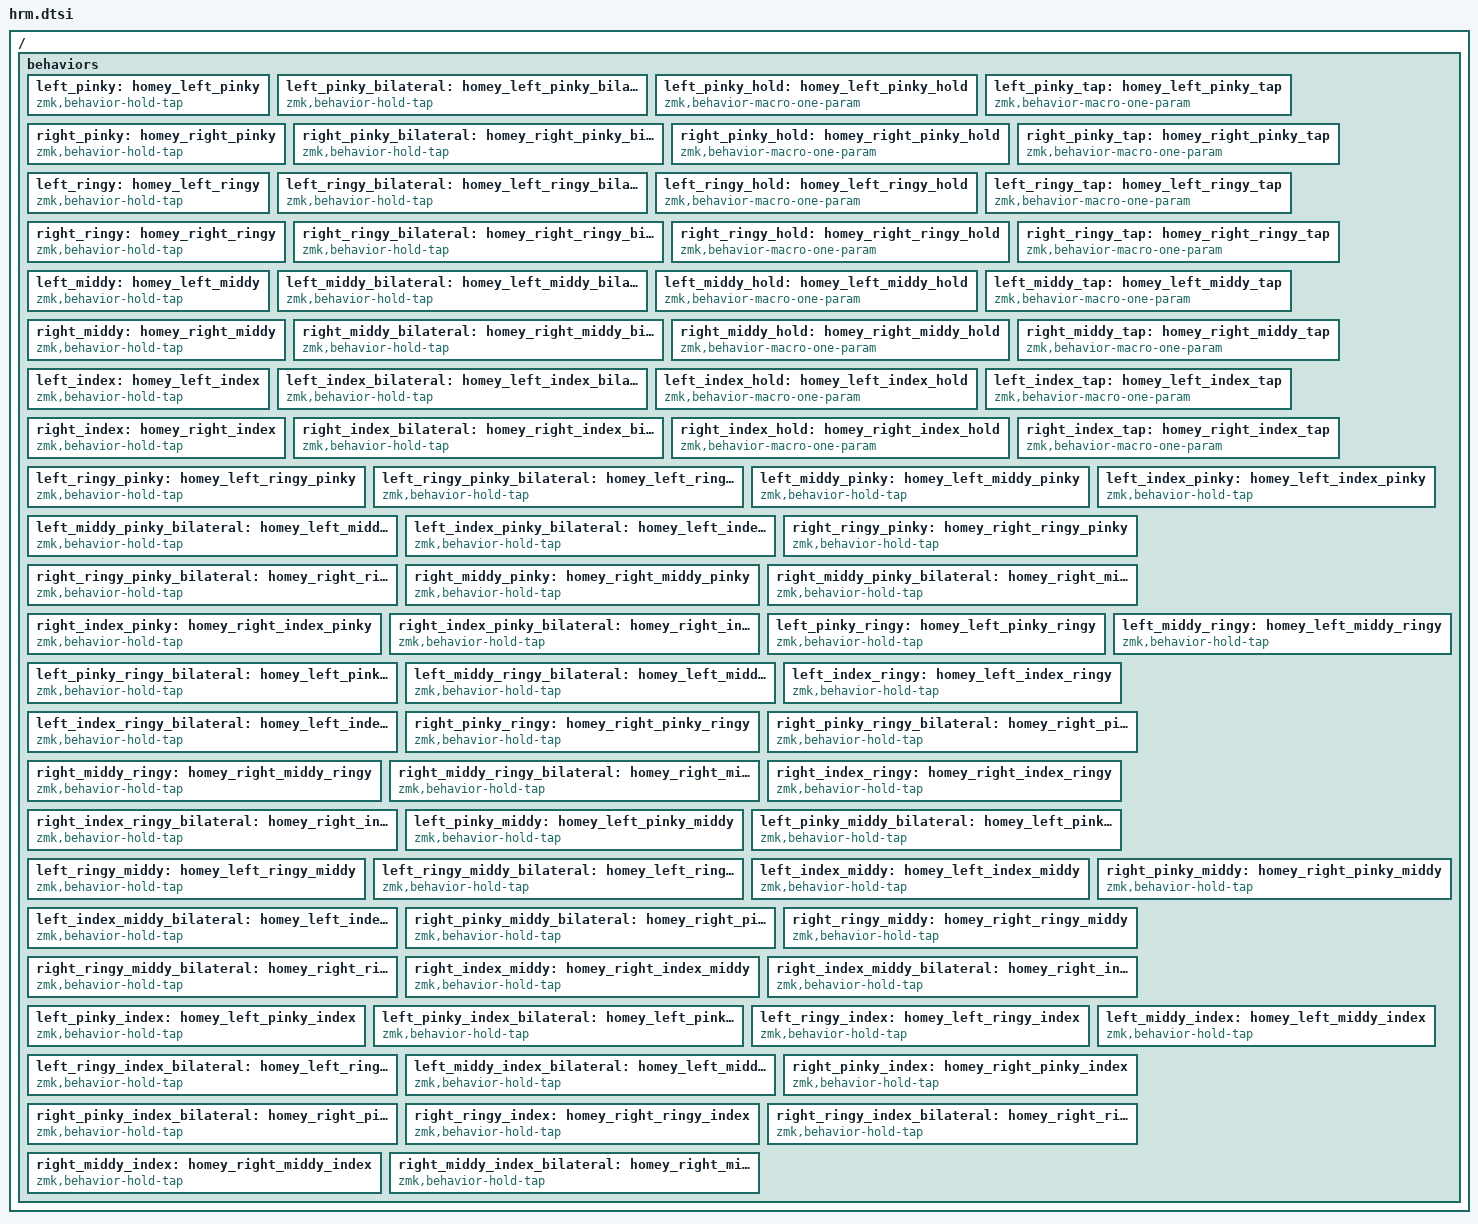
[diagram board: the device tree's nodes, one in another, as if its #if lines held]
/ {
  behaviors {

    //////////////////////////////////////////////////////////////////////////
    //
    // Miryoku layers and home row mods (ported from my QMK endgame)
    // - https://sunaku.github.io/home-row-mods.html#porting-to-zmk
    // - https://github.com/urob/zmk-config#timeless-homerow-mods
    //
    //////////////////////////////////////////////////////////////////////////

    //
    // DIFFICULTY_LEVEL specifies your level of expertise with this keymap.
    // It's meant to help newcomers gradually work their way up to mastery.
    //
    // #define DIFFICULTY_LEVEL 1 // novice (500ms)
    // #define DIFFICULTY_LEVEL 2 // slower (400ms)
    // #define DIFFICULTY_LEVEL 3 // normal (300ms)
    // #define DIFFICULTY_LEVEL 4 // faster (200ms)
    // #define DIFFICULTY_LEVEL 5 // expert (100ms)
    //
    // You can disable this setting by omitting it or assigning a `0` zero,
    // in which case it will default to my personal set of time thresholds.
    //
    // #define DIFFICULTY_LEVEL 0 // sunaku (150ms)
    //
    // No matter what difficulty level you choose, you can always override
    // any settings in this keymap at the beginning of this configuration.
    //
    #ifdef DIFFICULTY_LEVEL
      #if DIFFICULTY_LEVEL > 0 && DIFFICULTY_LEVEL < 6
        #ifndef TAPPING_RESOLUTION
          #define TAPPING_RESOLUTION ((6 - DIFFICULTY_LEVEL) * 100)
        #endif
      #endif
    #endif

    //
    // TAPPING_RESOLUTION specifies the maximum speed at which the keyboard
    // confuses your taps as being holds when you type on home row mod keys.
    // When you lower this value, the same confusion should still occur; but
    // when you raise this value, you should be able to type normally again.
    //
    #ifndef TAPPING_RESOLUTION
    #define TAPPING_RESOLUTION 150
    #endif

    //
    // ENFORCE_BILATERAL cancels out single-handed home row mods activation by
    // releasing any currently pressed mods and replacing them with plain taps.
    //
    // NOTE: You may still encounter "flashing mods" where an operating system
    // action is triggered by the release of mods, such as LGUI which launches
    // the Windows Start Menu and LALT which opens the Microsoft Office Ribbon.
    //
    //#define ENFORCE_BILATERAL

    //
    // SHIFT_FORGIVENESS taps when home row shift is merely held and released,
    // without any other key having been tapped while the shift was held down.
    // For example, suppose you hold a home row shift key and, before pressing
    // another key, you suddenly decide that you don't want the shift anymore:
    //
    // <1> If this setting is enabled, the underlying tap behavior is triggered
    //     to type a single character when you release that home row shift key.
    //
    // <2> Otherwise, nothing happens when you release that home row shift key.
    //
    // This requires the "hold-while-undecided" ZMK feature in a beta firmware:
    // please select "v24.08-beta1" or newer from the drop-down menu located at
    // Glove80 Layout Editor > Settings > Advanced Settings > Firmware Version.
    //
    // CAUTION: This can interfere with mod-click mouse usage where you hold a
    // home row shift key and perform mouse actions (move, click, drag & drop):
    // when you release that home row shift key, its underlying character would
    // be typed, potentially triggering an unexpected action on your selection!
    // To prevent the underlying character from being typed, press another key
    // (such as a dedicated shift key, a neighboring home row mod key, or even
    // a layer access key) before you release the original home row shift key.
    //
    // NOTE: You may potentially encounter "flashing mods" where an application
    // or operating system action is triggered by a standalone tap of a shift,
    // but this is unlikely as people regularly tap shift without consequence.
    //
    //#define SHIFT_FORGIVENESS

    //
    // THUMB_FORGIVENESS taps when a thumb layer access key is merely held and
    // released, without any other key having been tapped while thumb was held.
    // For example, suppose you hold the cursor layer key and, before pressing
    // another key, you suddenly decide that you don't want the layer anymore:
    //
    // <1> If this setting is enabled, the underlying tap behavior is triggered
    //     to type a single character when you release that layer access key.
    //
    // <2> Otherwise, nothing happens when you release that layer access key.
    //
    // NOTE: This setting interferes with (and effectively disables) per-key
    // RGB indicators (PR30) for layers accessed via thumb layer access keys.
    //
    //#define THUMB_FORGIVENESS

    //
    // SPACE_FORGIVENESS taps when the symbol layer access key is merely held
    // and released, without any symbol been tapped while the access was held.
    // For example, suppose you hold the symbol layer key and, before pressing
    // another key, you suddenly decide that you don't want the layer anymore:
    //
    // <1> If this setting is enabled, the underlying tap behavior is triggered
    //     to type a single character when you release that layer access key.
    //
    // <2> Otherwise, nothing happens when you release that layer access key.
    //
    // NOTE: This setting interferes with (and effectively disables) per-key
    // RGB indicators (PR30) for layers accessed via thumb layer access keys.
    //
    //#define SPACE_FORGIVENESS

    //
    // The *_FINGER_MOD specify which modifiers are used by home row mod keys.
    // Here, we use Miryoku's "GACS" (Win, Alt, Ctrl, Shift) order by default,
    // unless OPERATING_SYSTEM is macOS, in which case Win & Ctrl are swapped,
    // unless MACOS_USE_GACS is also defined to suppress that Win & Ctrl swap.
    //
    #ifndef PINKY_FINGER_MOD
      #if OPERATING_SYSTEM == 'M' && !defined(MACOS_USE_GACS)
        #define PINKY_FINGER_MOD LCTL
      #else
        #define PINKY_FINGER_MOD LGUI
      #endif
    #endif
    #ifndef RINGY_FINGER_MOD
    #define RINGY_FINGER_MOD LALT
    #endif
    #ifndef MIDDY_FINGER_MOD
      #if OPERATING_SYSTEM == 'M' && !defined(MACOS_USE_GACS)
        #define MIDDY_FINGER_MOD LGUI
      #else
        #define MIDDY_FINGER_MOD LCTL
      #endif
    #endif
    #ifndef INDEX_FINGER_MOD
    #define INDEX_FINGER_MOD LSFT
    #endif
    //
    // The following settings let you configure mods individually, per finger:
    //
    #ifndef LEFT_PINKY_MOD
    #define LEFT_PINKY_MOD PINKY_FINGER_MOD
    #endif
    #ifndef RIGHT_PINKY_MOD
    #define RIGHT_PINKY_MOD PINKY_FINGER_MOD
    #endif
    #ifndef LEFT_RINGY_MOD
    #define LEFT_RINGY_MOD RINGY_FINGER_MOD
    #endif
    #ifndef RIGHT_RINGY_MOD
    #define RIGHT_RINGY_MOD RINGY_FINGER_MOD
    #endif
    #ifndef LEFT_MIDDY_MOD
    #define LEFT_MIDDY_MOD MIDDY_FINGER_MOD
    #endif
    #ifndef RIGHT_MIDDY_MOD
    #define RIGHT_MIDDY_MOD MIDDY_FINGER_MOD
    #endif
    #ifndef LEFT_INDEX_MOD
    #define LEFT_INDEX_MOD INDEX_FINGER_MOD
    #endif
    #ifndef RIGHT_INDEX_MOD
    #define RIGHT_INDEX_MOD INDEX_FINGER_MOD
    #endif

    //
    // HOMEY_HOLDING_TYPE defines the flavor of ZMK hold-tap behavior to use
    // for the pinky, ring, and middle fingers (which are assigned to Super,
    // Alt, and Ctrl respectively in the Miryoku system) on home row keys.
    //
    #ifndef HOMEY_HOLDING_TYPE
    #define HOMEY_HOLDING_TYPE "tap-preferred"
    #endif

    //
    // HOMEY_HOLDING_TIME defines how long you need to hold (milliseconds)
    // home row mod keys in order to send their modifiers to the computer
    // (i.e. "register" them) for mod-click mouse usage (e.g. Ctrl-Click).
    //
    #ifndef HOMEY_HOLDING_TIME
    #define HOMEY_HOLDING_TIME (TAPPING_RESOLUTION + 90)
    #endif
    #ifndef INDEX_HOLDING_TIME
    #define INDEX_HOLDING_TIME (TAPPING_RESOLUTION + 20)
    #endif
    #ifndef MIDDY_HOLDING_TIME
    #define MIDDY_HOLDING_TIME (TAPPING_RESOLUTION + 60)
    #endif
    #ifndef RINGY_HOLDING_TIME
    #define RINGY_HOLDING_TIME (TAPPING_RESOLUTION + 90)
    #endif
    #ifndef PINKY_HOLDING_TIME
    #define PINKY_HOLDING_TIME (TAPPING_RESOLUTION + 110)
    #endif

    //
    // HOMEY_STREAK_DECAY defines how long you need to wait (milliseconds)
    // after typing before you can use home row mods again.  It prevents
    // unintended activation of home row mods when you're actively typing.
    //
    #ifndef HOMEY_STREAK_DECAY
    #define HOMEY_STREAK_DECAY TAPPING_RESOLUTION
    #endif

    //
    // HOMEY_REPEAT_DECAY defines how much time you have left (milliseconds)
    // after tapping a key to hold it again in order to make it auto-repeat.
    //
    #ifndef HOMEY_REPEAT_DECAY
    #define HOMEY_REPEAT_DECAY (TAPPING_RESOLUTION + 150)
    #endif // "tap then hold" for key auto-repeat

    //
    // CHORD_HOLDING_TYPE defines the flavor of ZMK hold-tap behavior to use
    // for chorded home row mods (secondary keypresses in multi-mod chords).
    //
    #ifndef CHORD_HOLDING_TYPE
    #define CHORD_HOLDING_TYPE HOMEY_HOLDING_TYPE
    #endif

    //
    // CHORD_HOLDING_TIME defines how long you need to hold (milliseconds)
    // home row mod keys in order to send their modifiers to the computer
    // (i.e. "register" them) for mod-click mouse usage (e.g. Ctrl-Click).
    // This is specifically for secondary keypresses in multi-mod chords.
    //
    #ifndef CHORD_HOLDING_TIME
    #define CHORD_HOLDING_TIME TAPPING_RESOLUTION
    #endif

    //
    // CHORD_STREAK_DECAY defines how long you need to wait (milliseconds)
    // after typing before you can use home row mods again.  It prevents
    // unintended activation of home row mods when you're actively typing
    // This is specifically for secondary keypresses in multi-mod chords.
    //
    #ifndef CHORD_STREAK_DECAY
    #define CHORD_STREAK_DECAY HOMEY_STREAK_DECAY
    #endif

    //
    // CHORD_REPEAT_DECAY defines how much time you have left (milliseconds)
    // after tapping a key to hold it again in order to make it auto-repeat.
    // This is specifically for secondary keypresses in multi-mod chords.
    //
    #ifndef CHORD_REPEAT_DECAY
    #define CHORD_REPEAT_DECAY HOMEY_REPEAT_DECAY
    #endif

    //
    // INDEX_HOLDING_TYPE defines the flavor of ZMK hold-tap behavior to use
    // for index fingers (which Miryoku assigns to Shift) on home row keys.
    //
    // NOTE: The "tap-preferred" flavor of ZMK hold-tap for index finger keys
    // allows faster activation of the Shift modifier (without having to wait
    // for the modified key to be released as the "balanced" flavor requires).
    //
    #ifndef INDEX_HOLDING_TYPE
    #define INDEX_HOLDING_TYPE "tap-preferred"
    #endif

    //
    // INDEX_STREAK_DECAY defines how long you need to wait (milliseconds)
    // after typing before you can use home row mods again.  It prevents
    // unintended activation of home row mods when you're actively typing.
    //
    #ifndef INDEX_STREAK_DECAY
    #define INDEX_STREAK_DECAY (TAPPING_RESOLUTION - 50)
    #endif

    //
    // INDEX_REPEAT_DECAY defines how much time you have left (milliseconds)
    // after tapping a key to hold it again in order to make it auto-repeat.
    //
    #ifndef INDEX_REPEAT_DECAY
    #define INDEX_REPEAT_DECAY (TAPPING_RESOLUTION + 150)
    #endif // "tap then hold" for key auto-repeat

    //
    // PLAIN_HOLDING_TYPE defines the flavor of ZMK hold-tap behavior to use
    // for index fingers (which Miryoku assigns to Shift) on home row keys.
    //
    // NOTE: The "tap-preferred" flavor of ZMK hold-tap for index finger keys
    // allows faster activation of the Shift modifier (without having to wait
    // for the modified key to be released as the "balanced" flavor requires).
    //
    #ifndef PLAIN_HOLDING_TYPE
    #define PLAIN_HOLDING_TYPE INDEX_HOLDING_TYPE
    #endif

    //
    // PLAIN_HOLDING_TIME defines how long you need to hold (milliseconds)
    // index finger keys in order to send their modifiers to the computer
    // (i.e. "register" them) for mod-click mouse usage (e.g. Shift-Click).
    //
    #ifndef PLAIN_HOLDING_TIME
    #define PLAIN_HOLDING_TIME (TAPPING_RESOLUTION + 50)
    #endif

    //
    // PLAIN_STREAK_DECAY defines how long you need to wait (milliseconds)
    // after typing before you can use home row mods again.  It prevents
    // unintended activation of home row mods when you're actively typing.
    //
    #ifndef PLAIN_STREAK_DECAY
    #define PLAIN_STREAK_DECAY HOMEY_STREAK_DECAY
    #endif

    //
    // PLAIN_REPEAT_DECAY defines how much time you have left (milliseconds)
    // after tapping a key to hold it again in order to make it auto-repeat.
    //
    #ifndef PLAIN_REPEAT_DECAY
    #define PLAIN_REPEAT_DECAY (TAPPING_RESOLUTION + 150)
    #endif // "tap then hold" for key auto-repeat

    //
    // THUMB_HOLDING_TYPE defines the flavor of ZMK hold-tap behavior to use
    // for the thumbs (which are assigned to 6 layers in the Miryoku system).
    //
    // NOTE: The "balanced" flavor of ZMK hold-tap provides instant modifier
    // activation for the symbol layer (if the tapped symbol key is released
    // while the thumb layer key is still held down) for quicker programming.
    //
    #ifndef THUMB_HOLDING_TYPE
    #define THUMB_HOLDING_TYPE "balanced"
    #endif

    //
    // THUMB_HOLDING_TIME defines how long you need to hold (milliseconds)
    // a thumb key to activate a layer.  Shorter holds are treated as taps.
    //
    #ifndef THUMB_HOLDING_TIME
    #define THUMB_HOLDING_TIME (TAPPING_RESOLUTION + 50)
    #endif

    //
    // THUMB_REPEAT_DECAY defines how much time you have left (milliseconds)
    // after tapping a key to hold it again in order to make it auto-repeat.
    //
    #ifndef THUMB_REPEAT_DECAY
    #define THUMB_REPEAT_DECAY (TAPPING_RESOLUTION + 150)
    #endif // "tap then hold" for key auto-repeat

    //
    // SPACE_HOLDING_TYPE defines the flavor of ZMK hold-tap behavior to use
    // for spacebar (assigned to the right thumb's home position by default).
    //
    #ifndef SPACE_HOLDING_TYPE
    #define SPACE_HOLDING_TYPE THUMB_HOLDING_TYPE
    #endif

    //
    // SPACE_HOLDING_TIME defines how long you need to hold (milliseconds)
    // the space thumb key to activate.  Shorter holds are treated as taps.
    //
    #ifndef SPACE_HOLDING_TIME
    #define SPACE_HOLDING_TIME (TAPPING_RESOLUTION + 20)
    #endif

    //
    // SPACE_REPEAT_DECAY defines how much time you have left (milliseconds)
    // after tapping a key to hold it again in order to make it auto-repeat.
    //
    #ifndef SPACE_REPEAT_DECAY
    #define SPACE_REPEAT_DECAY TAPPING_RESOLUTION
    #endif

    //        34 KEY MATRIX / LAYOUT MAPPING
    //
    // ╭────────────────────┬────────────────────╮
    // │  0   1   2   3   4 │  5   6   7   8   9 │
    // │ 10  11  12  13  14 │ 15  16  17  18  19 │
    // │ 20  21  22  23  24 │ 25  26  27  28  29 │
    // ╰───────────╮ 30  31 │ 32  33 ╭───────────╯
    //             ╰────────┴────────╯
    #define LEFT_HAND_KEYS  \
            0  1  2  3  4   \
           10 11 12 13 14   \
           20 21 22 23 24
    #define RIGHT_HAND_KEYS \
            5  6  7  8  9   \
           15 16 17 18 19   \
           25 26 27 28 29
    #define THUMB_KEYS      \
           30 31    32 33

    #define LEFT_PINKY_KEY  A
    #define LEFT_RINGY_KEY  O
    #define LEFT_MIDDY_KEY  E
    #define LEFT_INDEX_KEY  U

    #define RIGHT_INDEX_KEY H
    #define RIGHT_MIDDY_KEY T
    #define RIGHT_RINGY_KEY N
    #define RIGHT_PINKY_KEY S

    //
    // Home row mods with bilateral combinations support
    //
    #ifndef PINKY_HOLDING_TYPE
    #define PINKY_HOLDING_TYPE HOMEY_HOLDING_TYPE
    #endif
    #ifndef PINKY_CHORD_HOLDING_TYPE
    #define PINKY_CHORD_HOLDING_TYPE CHORD_HOLDING_TYPE
    #endif
    #ifndef LEFT_PINKY_CHORD_HOLDING_TYPE
    #define LEFT_PINKY_CHORD_HOLDING_TYPE PINKY_CHORD_HOLDING_TYPE
    #endif
    #ifndef RIGHT_PINKY_CHORD_HOLDING_TYPE
    #define RIGHT_PINKY_CHORD_HOLDING_TYPE PINKY_CHORD_HOLDING_TYPE
    #endif
    #ifndef PINKY_HOLDING_TIME
    #define PINKY_HOLDING_TIME HOMEY_HOLDING_TIME
    #endif
    #ifndef PINKY_CHORD_HOLDING_TIME
    #define PINKY_CHORD_HOLDING_TIME CHORD_HOLDING_TIME
    #endif
    #ifndef LEFT_PINKY_CHORD_HOLDING_TIME
    #define LEFT_PINKY_CHORD_HOLDING_TIME PINKY_CHORD_HOLDING_TIME
    #endif
    #ifndef RIGHT_PINKY_CHORD_HOLDING_TIME
    #define RIGHT_PINKY_CHORD_HOLDING_TIME PINKY_CHORD_HOLDING_TIME
    #endif
    #ifndef PINKY_STREAK_DECAY
    #define PINKY_STREAK_DECAY HOMEY_STREAK_DECAY
    #endif
    #ifndef PINKY_CHORD_STREAK_DECAY
    #define PINKY_CHORD_STREAK_DECAY CHORD_STREAK_DECAY
    #endif
    #ifndef LEFT_PINKY_CHORD_STREAK_DECAY
    #define LEFT_PINKY_CHORD_STREAK_DECAY PINKY_CHORD_STREAK_DECAY
    #endif
    #ifndef RIGHT_PINKY_CHORD_STREAK_DECAY
    #define RIGHT_PINKY_CHORD_STREAK_DECAY PINKY_CHORD_STREAK_DECAY
    #endif
    #ifndef PINKY_REPEAT_DECAY
    #define PINKY_REPEAT_DECAY HOMEY_REPEAT_DECAY
    #endif
    #ifndef PINKY_CHORD_REPEAT_DECAY
    #define PINKY_CHORD_REPEAT_DECAY CHORD_REPEAT_DECAY
    #endif
    #ifndef LEFT_PINKY_CHORD_REPEAT_DECAY
    #define LEFT_PINKY_CHORD_REPEAT_DECAY PINKY_CHORD_REPEAT_DECAY
    #endif
    #ifndef RIGHT_PINKY_CHORD_REPEAT_DECAY
    #define RIGHT_PINKY_CHORD_REPEAT_DECAY PINKY_CHORD_REPEAT_DECAY
    #endif
    #ifndef RINGY_HOLDING_TYPE
    #define RINGY_HOLDING_TYPE HOMEY_HOLDING_TYPE
    #endif
    #ifndef RINGY_CHORD_HOLDING_TYPE
    #define RINGY_CHORD_HOLDING_TYPE CHORD_HOLDING_TYPE
    #endif
    #ifndef LEFT_RINGY_CHORD_HOLDING_TYPE
    #define LEFT_RINGY_CHORD_HOLDING_TYPE RINGY_CHORD_HOLDING_TYPE
    #endif
    #ifndef RIGHT_RINGY_CHORD_HOLDING_TYPE
    #define RIGHT_RINGY_CHORD_HOLDING_TYPE RINGY_CHORD_HOLDING_TYPE
    #endif
    #ifndef RINGY_HOLDING_TIME
    #define RINGY_HOLDING_TIME HOMEY_HOLDING_TIME
    #endif
    #ifndef RINGY_CHORD_HOLDING_TIME
    #define RINGY_CHORD_HOLDING_TIME CHORD_HOLDING_TIME
    #endif
    #ifndef LEFT_RINGY_CHORD_HOLDING_TIME
    #define LEFT_RINGY_CHORD_HOLDING_TIME RINGY_CHORD_HOLDING_TIME
    #endif
    #ifndef RIGHT_RINGY_CHORD_HOLDING_TIME
    #define RIGHT_RINGY_CHORD_HOLDING_TIME RINGY_CHORD_HOLDING_TIME
    #endif
    #ifndef RINGY_STREAK_DECAY
    #define RINGY_STREAK_DECAY HOMEY_STREAK_DECAY
    #endif
    #ifndef RINGY_CHORD_STREAK_DECAY
    #define RINGY_CHORD_STREAK_DECAY CHORD_STREAK_DECAY
    #endif
    #ifndef LEFT_RINGY_CHORD_STREAK_DECAY
    #define LEFT_RINGY_CHORD_STREAK_DECAY RINGY_CHORD_STREAK_DECAY
    #endif
    #ifndef RIGHT_RINGY_CHORD_STREAK_DECAY
    #define RIGHT_RINGY_CHORD_STREAK_DECAY RINGY_CHORD_STREAK_DECAY
    #endif
    #ifndef RINGY_REPEAT_DECAY
    #define RINGY_REPEAT_DECAY HOMEY_REPEAT_DECAY
    #endif
    #ifndef RINGY_CHORD_REPEAT_DECAY
    #define RINGY_CHORD_REPEAT_DECAY CHORD_REPEAT_DECAY
    #endif
    #ifndef LEFT_RINGY_CHORD_REPEAT_DECAY
    #define LEFT_RINGY_CHORD_REPEAT_DECAY RINGY_CHORD_REPEAT_DECAY
    #endif
    #ifndef RIGHT_RINGY_CHORD_REPEAT_DECAY
    #define RIGHT_RINGY_CHORD_REPEAT_DECAY RINGY_CHORD_REPEAT_DECAY
    #endif
    #ifndef MIDDY_HOLDING_TYPE
    #define MIDDY_HOLDING_TYPE HOMEY_HOLDING_TYPE
    #endif
    #ifndef MIDDY_CHORD_HOLDING_TYPE
    #define MIDDY_CHORD_HOLDING_TYPE CHORD_HOLDING_TYPE
    #endif
    #ifndef LEFT_MIDDY_CHORD_HOLDING_TYPE
    #define LEFT_MIDDY_CHORD_HOLDING_TYPE MIDDY_CHORD_HOLDING_TYPE
    #endif
    #ifndef RIGHT_MIDDY_CHORD_HOLDING_TYPE
    #define RIGHT_MIDDY_CHORD_HOLDING_TYPE MIDDY_CHORD_HOLDING_TYPE
    #endif
    #ifndef MIDDY_HOLDING_TIME
    #define MIDDY_HOLDING_TIME HOMEY_HOLDING_TIME
    #endif
    #ifndef MIDDY_CHORD_HOLDING_TIME
    #define MIDDY_CHORD_HOLDING_TIME CHORD_HOLDING_TIME
    #endif
    #ifndef LEFT_MIDDY_CHORD_HOLDING_TIME
    #define LEFT_MIDDY_CHORD_HOLDING_TIME MIDDY_CHORD_HOLDING_TIME
    #endif
    #ifndef RIGHT_MIDDY_CHORD_HOLDING_TIME
    #define RIGHT_MIDDY_CHORD_HOLDING_TIME MIDDY_CHORD_HOLDING_TIME
    #endif
    #ifndef MIDDY_STREAK_DECAY
    #define MIDDY_STREAK_DECAY HOMEY_STREAK_DECAY
    #endif
    #ifndef MIDDY_CHORD_STREAK_DECAY
    #define MIDDY_CHORD_STREAK_DECAY CHORD_STREAK_DECAY
    #endif
    #ifndef LEFT_MIDDY_CHORD_STREAK_DECAY
    #define LEFT_MIDDY_CHORD_STREAK_DECAY MIDDY_CHORD_STREAK_DECAY
    #endif
    #ifndef RIGHT_MIDDY_CHORD_STREAK_DECAY
    #define RIGHT_MIDDY_CHORD_STREAK_DECAY MIDDY_CHORD_STREAK_DECAY
    #endif
    #ifndef MIDDY_REPEAT_DECAY
    #define MIDDY_REPEAT_DECAY HOMEY_REPEAT_DECAY
    #endif
    #ifndef MIDDY_CHORD_REPEAT_DECAY
    #define MIDDY_CHORD_REPEAT_DECAY CHORD_REPEAT_DECAY
    #endif
    #ifndef LEFT_MIDDY_CHORD_REPEAT_DECAY
    #define LEFT_MIDDY_CHORD_REPEAT_DECAY MIDDY_CHORD_REPEAT_DECAY
    #endif
    #ifndef RIGHT_MIDDY_CHORD_REPEAT_DECAY
    #define RIGHT_MIDDY_CHORD_REPEAT_DECAY MIDDY_CHORD_REPEAT_DECAY
    #endif
    #ifndef INDEX_HOLDING_TYPE
    #define INDEX_HOLDING_TYPE HOMEY_HOLDING_TYPE
    #endif
    #ifndef INDEX_CHORD_HOLDING_TYPE
    #define INDEX_CHORD_HOLDING_TYPE CHORD_HOLDING_TYPE
    #endif
    #ifndef LEFT_INDEX_CHORD_HOLDING_TYPE
    #define LEFT_INDEX_CHORD_HOLDING_TYPE INDEX_CHORD_HOLDING_TYPE
    #endif
    #ifndef RIGHT_INDEX_CHORD_HOLDING_TYPE
    #define RIGHT_INDEX_CHORD_HOLDING_TYPE INDEX_CHORD_HOLDING_TYPE
    #endif
    #ifndef INDEX_HOLDING_TIME
    #define INDEX_HOLDING_TIME HOMEY_HOLDING_TIME
    #endif
    #ifndef INDEX_CHORD_HOLDING_TIME
    #define INDEX_CHORD_HOLDING_TIME CHORD_HOLDING_TIME
    #endif
    #ifndef LEFT_INDEX_CHORD_HOLDING_TIME
    #define LEFT_INDEX_CHORD_HOLDING_TIME INDEX_CHORD_HOLDING_TIME
    #endif
    #ifndef RIGHT_INDEX_CHORD_HOLDING_TIME
    #define RIGHT_INDEX_CHORD_HOLDING_TIME INDEX_CHORD_HOLDING_TIME
    #endif
    #ifndef INDEX_STREAK_DECAY
    #define INDEX_STREAK_DECAY HOMEY_STREAK_DECAY
    #endif
    #ifndef INDEX_CHORD_STREAK_DECAY
    #define INDEX_CHORD_STREAK_DECAY CHORD_STREAK_DECAY
    #endif
    #ifndef LEFT_INDEX_CHORD_STREAK_DECAY
    #define LEFT_INDEX_CHORD_STREAK_DECAY INDEX_CHORD_STREAK_DECAY
    #endif
    #ifndef RIGHT_INDEX_CHORD_STREAK_DECAY
    #define RIGHT_INDEX_CHORD_STREAK_DECAY INDEX_CHORD_STREAK_DECAY
    #endif
    #ifndef INDEX_REPEAT_DECAY
    #define INDEX_REPEAT_DECAY HOMEY_REPEAT_DECAY
    #endif
    #ifndef INDEX_CHORD_REPEAT_DECAY
    #define INDEX_CHORD_REPEAT_DECAY CHORD_REPEAT_DECAY
    #endif
    #ifndef LEFT_INDEX_CHORD_REPEAT_DECAY
    #define LEFT_INDEX_CHORD_REPEAT_DECAY INDEX_CHORD_REPEAT_DECAY
    #endif
    #ifndef RIGHT_INDEX_CHORD_REPEAT_DECAY
    #define RIGHT_INDEX_CHORD_REPEAT_DECAY INDEX_CHORD_REPEAT_DECAY
    #endif
    #ifndef LEFT_PINKY_HOLDING_TYPE
    #define LEFT_PINKY_HOLDING_TYPE PINKY_HOLDING_TYPE
    #endif
    #ifndef LEFT_PINKY_HOLDING_TIME
    #define LEFT_PINKY_HOLDING_TIME PINKY_HOLDING_TIME
    #endif
    #ifndef LEFT_PINKY_STREAK_DECAY
    #define LEFT_PINKY_STREAK_DECAY PINKY_STREAK_DECAY
    #endif
    #ifndef LEFT_PINKY_REPEAT_DECAY
    #define LEFT_PINKY_REPEAT_DECAY PINKY_REPEAT_DECAY
    #endif
    left_pinky: homey_left_pinky {
      compatible = "zmk,behavior-hold-tap";
      flavor = LEFT_PINKY_HOLDING_TYPE;
      hold-trigger-key-positions = <RIGHT_HAND_KEYS THUMB_KEYS>;
      hold-trigger-on-release; // wait for other home row mods
      tapping-term-ms = <LEFT_PINKY_HOLDING_TIME>;
      quick-tap-ms = <LEFT_PINKY_REPEAT_DECAY>;
      require-prior-idle-ms = <LEFT_PINKY_STREAK_DECAY>;
      #binding-cells = <2>;
      bindings = <&kp>, <&kp>;
      #ifdef SHIFT_FORGIVENESS
      #if LEFT_PINKY_MOD == LSFT || LEFT_PINKY_MOD == RSFT
      hold-while-undecided; // requires 24.08-beta1 or newer firmware
      retro-tap; // tap on standalone hold
      #endif
      #endif
    };
    left_pinky_bilateral: homey_left_pinky_bilateral {
      compatible = "zmk,behavior-hold-tap";
      flavor = LEFT_PINKY_HOLDING_TYPE;
      hold-trigger-key-positions = <RIGHT_HAND_KEYS THUMB_KEYS>;
      hold-trigger-on-release; // wait for other home row mods
      tapping-term-ms = <LEFT_PINKY_HOLDING_TIME>;
      quick-tap-ms = <LEFT_PINKY_REPEAT_DECAY>;
      require-prior-idle-ms = <LEFT_PINKY_STREAK_DECAY>;
      #binding-cells = <2>;
      bindings = <&left_pinky_hold>, <&kp>;
      #ifdef SHIFT_FORGIVENESS
      #if LEFT_PINKY_MOD == LSFT || LEFT_PINKY_MOD == RSFT
      hold-while-undecided; // requires 24.08-beta1 or newer firmware
      retro-tap; // tap on standalone hold
      #endif
      #endif
    };
    left_pinky_hold: homey_left_pinky_hold {
      compatible = "zmk,behavior-macro-one-param";
      wait-ms = <0>;
      tap-ms = <0>;
      #binding-cells = <1>;
      bindings
        = <&macro_param_1to1>
        , <&macro_press &kp MACRO_PLACEHOLDER>
        #ifdef LAYER_LeftPinky
        , <&macro_press &mo LAYER_LeftPinky>
        #endif
        , <&macro_pause_for_release>
        , <&macro_param_1to1>
        , <&macro_release &kp MACRO_PLACEHOLDER>
        #ifdef LAYER_LeftPinky
        , <&macro_release &mo LAYER_LeftPinky>
        #endif
        ;
    };
    left_pinky_tap: homey_left_pinky_tap {
      compatible = "zmk,behavior-macro-one-param";
      wait-ms = <0>;
      tap-ms = <0>;
      #binding-cells = <1>;
      bindings
        = <&macro_release
            &kp LSFT &kp RSFT
            &kp LALT &kp RALT
            &kp LCTL &kp RCTL
            &kp LGUI &kp RGUI>
        , <&macro_tap &kp LEFT_PINKY_KEY>
        , <&macro_param_1to1>
        , <&macro_tap &kp MACRO_PLACEHOLDER>
        ;
    };
    #define LeftPinky(key) LeftPinky_layer0(key)
    #ifdef ENFORCE_BILATERAL
    #define left_pinky_layer0_variant left_pinky_bilateral
    #else
    #define left_pinky_layer0_variant left_pinky
    #endif
    #define LeftPinky_layer0(key) left_pinky_layer0_variant LEFT_PINKY_MOD key
    #ifndef RIGHT_PINKY_HOLDING_TYPE
    #define RIGHT_PINKY_HOLDING_TYPE PINKY_HOLDING_TYPE
    #endif
    #ifndef RIGHT_PINKY_HOLDING_TIME
    #define RIGHT_PINKY_HOLDING_TIME PINKY_HOLDING_TIME
    #endif
    #ifndef RIGHT_PINKY_STREAK_DECAY
    #define RIGHT_PINKY_STREAK_DECAY PINKY_STREAK_DECAY
    #endif
    #ifndef RIGHT_PINKY_REPEAT_DECAY
    #define RIGHT_PINKY_REPEAT_DECAY PINKY_REPEAT_DECAY
    #endif
    right_pinky: homey_right_pinky {
      compatible = "zmk,behavior-hold-tap";
      flavor = RIGHT_PINKY_HOLDING_TYPE;
      hold-trigger-key-positions = <LEFT_HAND_KEYS THUMB_KEYS>;
      hold-trigger-on-release; // wait for other home row mods
      tapping-term-ms = <RIGHT_PINKY_HOLDING_TIME>;
      quick-tap-ms = <RIGHT_PINKY_REPEAT_DECAY>;
      require-prior-idle-ms = <RIGHT_PINKY_STREAK_DECAY>;
      #binding-cells = <2>;
      bindings = <&kp>, <&kp>;
      #ifdef SHIFT_FORGIVENESS
      #if RIGHT_PINKY_MOD == LSFT || RIGHT_PINKY_MOD == RSFT
      hold-while-undecided; // requires 24.08-beta1 or newer firmware
      retro-tap; // tap on standalone hold
      #endif
      #endif
    };
    right_pinky_bilateral: homey_right_pinky_bilateral {
      compatible = "zmk,behavior-hold-tap";
      flavor = RIGHT_PINKY_HOLDING_TYPE;
      hold-trigger-key-positions = <LEFT_HAND_KEYS THUMB_KEYS>;
      hold-trigger-on-release; // wait for other home row mods
      tapping-term-ms = <RIGHT_PINKY_HOLDING_TIME>;
      quick-tap-ms = <RIGHT_PINKY_REPEAT_DECAY>;
      require-prior-idle-ms = <RIGHT_PINKY_STREAK_DECAY>;
      #binding-cells = <2>;
      bindings = <&right_pinky_hold>, <&kp>;
      #ifdef SHIFT_FORGIVENESS
      #if RIGHT_PINKY_MOD == LSFT || RIGHT_PINKY_MOD == RSFT
      hold-while-undecided; // requires 24.08-beta1 or newer firmware
      retro-tap; // tap on standalone hold
      #endif
      #endif
    };
    right_pinky_hold: homey_right_pinky_hold {
      compatible = "zmk,behavior-macro-one-param";
      wait-ms = <0>;
      tap-ms = <0>;
      #binding-cells = <1>;
      bindings
        = <&macro_param_1to1>
        , <&macro_press &kp MACRO_PLACEHOLDER>
        #ifdef LAYER_RightPinky
        , <&macro_press &mo LAYER_RightPinky>
        #endif
        , <&macro_pause_for_release>
        , <&macro_param_1to1>
        , <&macro_release &kp MACRO_PLACEHOLDER>
        #ifdef LAYER_RightPinky
        , <&macro_release &mo LAYER_RightPinky>
        #endif
        ;
    };
    right_pinky_tap: homey_right_pinky_tap {
      compatible = "zmk,behavior-macro-one-param";
      wait-ms = <0>;
      tap-ms = <0>;
      #binding-cells = <1>;
      bindings
        = <&macro_release
            &kp LSFT &kp RSFT
            &kp LALT &kp RALT
            &kp LCTL &kp RCTL
            &kp LGUI &kp RGUI>
        , <&macro_tap &kp RIGHT_PINKY_KEY>
        , <&macro_param_1to1>
        , <&macro_tap &kp MACRO_PLACEHOLDER>
        ;
    };
    #define RightPinky(key) RightPinky_layer0(key)
    #ifdef ENFORCE_BILATERAL
    #define right_pinky_layer0_variant right_pinky_bilateral
    #else
    #define right_pinky_layer0_variant right_pinky
    #endif
    #define RightPinky_layer0(key) right_pinky_layer0_variant RIGHT_PINKY_MOD key
    #ifndef LEFT_RINGY_HOLDING_TYPE
    #define LEFT_RINGY_HOLDING_TYPE RINGY_HOLDING_TYPE
    #endif
    #ifndef LEFT_RINGY_HOLDING_TIME
    #define LEFT_RINGY_HOLDING_TIME RINGY_HOLDING_TIME
    #endif
    #ifndef LEFT_RINGY_STREAK_DECAY
    #define LEFT_RINGY_STREAK_DECAY RINGY_STREAK_DECAY
    #endif
    #ifndef LEFT_RINGY_REPEAT_DECAY
    #define LEFT_RINGY_REPEAT_DECAY RINGY_REPEAT_DECAY
    #endif
    left_ringy: homey_left_ringy {
      compatible = "zmk,behavior-hold-tap";
      flavor = LEFT_RINGY_HOLDING_TYPE;
      hold-trigger-key-positions = <RIGHT_HAND_KEYS THUMB_KEYS>;
      hold-trigger-on-release; // wait for other home row mods
      tapping-term-ms = <LEFT_RINGY_HOLDING_TIME>;
      quick-tap-ms = <LEFT_RINGY_REPEAT_DECAY>;
      require-prior-idle-ms = <LEFT_RINGY_STREAK_DECAY>;
      #binding-cells = <2>;
      bindings = <&kp>, <&kp>;
      #ifdef SHIFT_FORGIVENESS
      #if LEFT_RINGY_MOD == LSFT || LEFT_RINGY_MOD == RSFT
      hold-while-undecided; // requires 24.08-beta1 or newer firmware
      retro-tap; // tap on standalone hold
      #endif
      #endif
    };
    left_ringy_bilateral: homey_left_ringy_bilateral {
      compatible = "zmk,behavior-hold-tap";
      flavor = LEFT_RINGY_HOLDING_TYPE;
      hold-trigger-key-positions = <RIGHT_HAND_KEYS THUMB_KEYS>;
      hold-trigger-on-release; // wait for other home row mods
      tapping-term-ms = <LEFT_RINGY_HOLDING_TIME>;
      quick-tap-ms = <LEFT_RINGY_REPEAT_DECAY>;
      require-prior-idle-ms = <LEFT_RINGY_STREAK_DECAY>;
      #binding-cells = <2>;
      bindings = <&left_ringy_hold>, <&kp>;
      #ifdef SHIFT_FORGIVENESS
      #if LEFT_RINGY_MOD == LSFT || LEFT_RINGY_MOD == RSFT
      hold-while-undecided; // requires 24.08-beta1 or newer firmware
      retro-tap; // tap on standalone hold
      #endif
      #endif
    };
    left_ringy_hold: homey_left_ringy_hold {
      compatible = "zmk,behavior-macro-one-param";
      wait-ms = <0>;
      tap-ms = <0>;
      #binding-cells = <1>;
      bindings
        = <&macro_param_1to1>
        , <&macro_press &kp MACRO_PLACEHOLDER>
        #ifdef LAYER_LeftRingy
        , <&macro_press &mo LAYER_LeftRingy>
        #endif
        , <&macro_pause_for_release>
        , <&macro_param_1to1>
        , <&macro_release &kp MACRO_PLACEHOLDER>
        #ifdef LAYER_LeftRingy
        , <&macro_release &mo LAYER_LeftRingy>
        #endif
        ;
    };
    left_ringy_tap: homey_left_ringy_tap {
      compatible = "zmk,behavior-macro-one-param";
      wait-ms = <0>;
      tap-ms = <0>;
      #binding-cells = <1>;
      bindings
        = <&macro_release
            &kp LSFT &kp RSFT
            &kp LALT &kp RALT
            &kp LCTL &kp RCTL
            &kp LGUI &kp RGUI>
        , <&macro_tap &kp LEFT_RINGY_KEY>
        , <&macro_param_1to1>
        , <&macro_tap &kp MACRO_PLACEHOLDER>
        ;
    };
    #define LeftRingy(key) LeftRingy_layer0(key)
    #ifdef ENFORCE_BILATERAL
    #define left_ringy_layer0_variant left_ringy_bilateral
    #else
    #define left_ringy_layer0_variant left_ringy
    #endif
    #define LeftRingy_layer0(key) left_ringy_layer0_variant LEFT_RINGY_MOD key
    #ifndef RIGHT_RINGY_HOLDING_TYPE
    #define RIGHT_RINGY_HOLDING_TYPE RINGY_HOLDING_TYPE
    #endif
    #ifndef RIGHT_RINGY_HOLDING_TIME
    #define RIGHT_RINGY_HOLDING_TIME RINGY_HOLDING_TIME
    #endif
    #ifndef RIGHT_RINGY_STREAK_DECAY
    #define RIGHT_RINGY_STREAK_DECAY RINGY_STREAK_DECAY
    #endif
    #ifndef RIGHT_RINGY_REPEAT_DECAY
    #define RIGHT_RINGY_REPEAT_DECAY RINGY_REPEAT_DECAY
    #endif
    right_ringy: homey_right_ringy {
      compatible = "zmk,behavior-hold-tap";
      flavor = RIGHT_RINGY_HOLDING_TYPE;
      hold-trigger-key-positions = <LEFT_HAND_KEYS THUMB_KEYS>;
      hold-trigger-on-release; // wait for other home row mods
      tapping-term-ms = <RIGHT_RINGY_HOLDING_TIME>;
      quick-tap-ms = <RIGHT_RINGY_REPEAT_DECAY>;
      require-prior-idle-ms = <RIGHT_RINGY_STREAK_DECAY>;
      #binding-cells = <2>;
      bindings = <&kp>, <&kp>;
      #ifdef SHIFT_FORGIVENESS
      #if RIGHT_RINGY_MOD == LSFT || RIGHT_RINGY_MOD == RSFT
      hold-while-undecided; // requires 24.08-beta1 or newer firmware
      retro-tap; // tap on standalone hold
      #endif
      #endif
    };
    right_ringy_bilateral: homey_right_ringy_bilateral {
      compatible = "zmk,behavior-hold-tap";
      flavor = RIGHT_RINGY_HOLDING_TYPE;
      hold-trigger-key-positions = <LEFT_HAND_KEYS THUMB_KEYS>;
      hold-trigger-on-release; // wait for other home row mods
      tapping-term-ms = <RIGHT_RINGY_HOLDING_TIME>;
      quick-tap-ms = <RIGHT_RINGY_REPEAT_DECAY>;
      require-prior-idle-ms = <RIGHT_RINGY_STREAK_DECAY>;
      #binding-cells = <2>;
      bindings = <&right_ringy_hold>, <&kp>;
      #ifdef SHIFT_FORGIVENESS
      #if RIGHT_RINGY_MOD == LSFT || RIGHT_RINGY_MOD == RSFT
      hold-while-undecided; // requires 24.08-beta1 or newer firmware
      retro-tap; // tap on standalone hold
      #endif
      #endif
    };
    right_ringy_hold: homey_right_ringy_hold {
      compatible = "zmk,behavior-macro-one-param";
      wait-ms = <0>;
      tap-ms = <0>;
      #binding-cells = <1>;
      bindings
        = <&macro_param_1to1>
        , <&macro_press &kp MACRO_PLACEHOLDER>
        #ifdef LAYER_RightRingy
        , <&macro_press &mo LAYER_RightRingy>
        #endif
        , <&macro_pause_for_release>
        , <&macro_param_1to1>
        , <&macro_release &kp MACRO_PLACEHOLDER>
        #ifdef LAYER_RightRingy
        , <&macro_release &mo LAYER_RightRingy>
        #endif
        ;
    };
    right_ringy_tap: homey_right_ringy_tap {
      compatible = "zmk,behavior-macro-one-param";
      wait-ms = <0>;
      tap-ms = <0>;
      #binding-cells = <1>;
      bindings
        = <&macro_release
            &kp LSFT &kp RSFT
            &kp LALT &kp RALT
            &kp LCTL &kp RCTL
            &kp LGUI &kp RGUI>
        , <&macro_tap &kp RIGHT_RINGY_KEY>
        , <&macro_param_1to1>
        , <&macro_tap &kp MACRO_PLACEHOLDER>
        ;
    };
    #define RightRingy(key) RightRingy_layer0(key)
    #ifdef ENFORCE_BILATERAL
    #define right_ringy_layer0_variant right_ringy_bilateral
    #else
    #define right_ringy_layer0_variant right_ringy
    #endif
    #define RightRingy_layer0(key) right_ringy_layer0_variant RIGHT_RINGY_MOD key
    #ifndef LEFT_MIDDY_HOLDING_TYPE
    #define LEFT_MIDDY_HOLDING_TYPE MIDDY_HOLDING_TYPE
    #endif
    #ifndef LEFT_MIDDY_HOLDING_TIME
    #define LEFT_MIDDY_HOLDING_TIME MIDDY_HOLDING_TIME
    #endif
    #ifndef LEFT_MIDDY_STREAK_DECAY
    #define LEFT_MIDDY_STREAK_DECAY MIDDY_STREAK_DECAY
    #endif
    #ifndef LEFT_MIDDY_REPEAT_DECAY
    #define LEFT_MIDDY_REPEAT_DECAY MIDDY_REPEAT_DECAY
    #endif
    left_middy: homey_left_middy {
      compatible = "zmk,behavior-hold-tap";
      flavor = LEFT_MIDDY_HOLDING_TYPE;
      hold-trigger-key-positions = <RIGHT_HAND_KEYS THUMB_KEYS>;
      hold-trigger-on-release; // wait for other home row mods
      tapping-term-ms = <LEFT_MIDDY_HOLDING_TIME>;
      quick-tap-ms = <LEFT_MIDDY_REPEAT_DECAY>;
      require-prior-idle-ms = <LEFT_MIDDY_STREAK_DECAY>;
      #binding-cells = <2>;
      bindings = <&kp>, <&kp>;
      #ifdef SHIFT_FORGIVENESS
      #if LEFT_MIDDY_MOD == LSFT || LEFT_MIDDY_MOD == RSFT
      hold-while-undecided; // requires 24.08-beta1 or newer firmware
      retro-tap; // tap on standalone hold
      #endif
      #endif
    };
    left_middy_bilateral: homey_left_middy_bilateral {
      compatible = "zmk,behavior-hold-tap";
      flavor = LEFT_MIDDY_HOLDING_TYPE;
      hold-trigger-key-positions = <RIGHT_HAND_KEYS THUMB_KEYS>;
      hold-trigger-on-release; // wait for other home row mods
      tapping-term-ms = <LEFT_MIDDY_HOLDING_TIME>;
      quick-tap-ms = <LEFT_MIDDY_REPEAT_DECAY>;
      require-prior-idle-ms = <LEFT_MIDDY_STREAK_DECAY>;
      #binding-cells = <2>;
      bindings = <&left_middy_hold>, <&kp>;
      #ifdef SHIFT_FORGIVENESS
      #if LEFT_MIDDY_MOD == LSFT || LEFT_MIDDY_MOD == RSFT
      hold-while-undecided; // requires 24.08-beta1 or newer firmware
      retro-tap; // tap on standalone hold
      #endif
      #endif
    };
    left_middy_hold: homey_left_middy_hold {
      compatible = "zmk,behavior-macro-one-param";
      wait-ms = <0>;
      tap-ms = <0>;
      #binding-cells = <1>;
      bindings
        = <&macro_param_1to1>
        , <&macro_press &kp MACRO_PLACEHOLDER>
        #ifdef LAYER_LeftMiddy
        , <&macro_press &mo LAYER_LeftMiddy>
        #endif
        , <&macro_pause_for_release>
        , <&macro_param_1to1>
        , <&macro_release &kp MACRO_PLACEHOLDER>
        #ifdef LAYER_LeftMiddy
        , <&macro_release &mo LAYER_LeftMiddy>
        #endif
        ;
    };
    left_middy_tap: homey_left_middy_tap {
      compatible = "zmk,behavior-macro-one-param";
      wait-ms = <0>;
      tap-ms = <0>;
      #binding-cells = <1>;
      bindings
        = <&macro_release
            &kp LSFT &kp RSFT
            &kp LALT &kp RALT
            &kp LCTL &kp RCTL
            &kp LGUI &kp RGUI>
        , <&macro_tap &kp LEFT_MIDDY_KEY>
        , <&macro_param_1to1>
        , <&macro_tap &kp MACRO_PLACEHOLDER>
        ;
    };
    #define LeftMiddy(key) LeftMiddy_layer0(key)
    #ifdef ENFORCE_BILATERAL
    #define left_middy_layer0_variant left_middy_bilateral
    #else
    #define left_middy_layer0_variant left_middy
    #endif
    #define LeftMiddy_layer0(key) left_middy_layer0_variant LEFT_MIDDY_MOD key
    #ifndef RIGHT_MIDDY_HOLDING_TYPE
    #define RIGHT_MIDDY_HOLDING_TYPE MIDDY_HOLDING_TYPE
    #endif
    #ifndef RIGHT_MIDDY_HOLDING_TIME
    #define RIGHT_MIDDY_HOLDING_TIME MIDDY_HOLDING_TIME
    #endif
    #ifndef RIGHT_MIDDY_STREAK_DECAY
    #define RIGHT_MIDDY_STREAK_DECAY MIDDY_STREAK_DECAY
    #endif
    #ifndef RIGHT_MIDDY_REPEAT_DECAY
    #define RIGHT_MIDDY_REPEAT_DECAY MIDDY_REPEAT_DECAY
    #endif
    right_middy: homey_right_middy {
      compatible = "zmk,behavior-hold-tap";
      flavor = RIGHT_MIDDY_HOLDING_TYPE;
      hold-trigger-key-positions = <LEFT_HAND_KEYS THUMB_KEYS>;
      hold-trigger-on-release; // wait for other home row mods
      tapping-term-ms = <RIGHT_MIDDY_HOLDING_TIME>;
      quick-tap-ms = <RIGHT_MIDDY_REPEAT_DECAY>;
      require-prior-idle-ms = <RIGHT_MIDDY_STREAK_DECAY>;
      #binding-cells = <2>;
      bindings = <&kp>, <&kp>;
      #ifdef SHIFT_FORGIVENESS
      #if RIGHT_MIDDY_MOD == LSFT || RIGHT_MIDDY_MOD == RSFT
      hold-while-undecided; // requires 24.08-beta1 or newer firmware
      retro-tap; // tap on standalone hold
      #endif
      #endif
    };
    right_middy_bilateral: homey_right_middy_bilateral {
      compatible = "zmk,behavior-hold-tap";
      flavor = RIGHT_MIDDY_HOLDING_TYPE;
      hold-trigger-key-positions = <LEFT_HAND_KEYS THUMB_KEYS>;
      hold-trigger-on-release; // wait for other home row mods
      tapping-term-ms = <RIGHT_MIDDY_HOLDING_TIME>;
      quick-tap-ms = <RIGHT_MIDDY_REPEAT_DECAY>;
      require-prior-idle-ms = <RIGHT_MIDDY_STREAK_DECAY>;
      #binding-cells = <2>;
      bindings = <&right_middy_hold>, <&kp>;
      #ifdef SHIFT_FORGIVENESS
      #if RIGHT_MIDDY_MOD == LSFT || RIGHT_MIDDY_MOD == RSFT
      hold-while-undecided; // requires 24.08-beta1 or newer firmware
      retro-tap; // tap on standalone hold
      #endif
      #endif
    };
    right_middy_hold: homey_right_middy_hold {
      compatible = "zmk,behavior-macro-one-param";
      wait-ms = <0>;
      tap-ms = <0>;
      #binding-cells = <1>;
      bindings
        = <&macro_param_1to1>
        , <&macro_press &kp MACRO_PLACEHOLDER>
        #ifdef LAYER_RightMiddy
        , <&macro_press &mo LAYER_RightMiddy>
        #endif
        , <&macro_pause_for_release>
        , <&macro_param_1to1>
        , <&macro_release &kp MACRO_PLACEHOLDER>
        #ifdef LAYER_RightMiddy
        , <&macro_release &mo LAYER_RightMiddy>
        #endif
        ;
    };
    right_middy_tap: homey_right_middy_tap {
      compatible = "zmk,behavior-macro-one-param";
      wait-ms = <0>;
      tap-ms = <0>;
      #binding-cells = <1>;
      bindings
        = <&macro_release
            &kp LSFT &kp RSFT
            &kp LALT &kp RALT
            &kp LCTL &kp RCTL
            &kp LGUI &kp RGUI>
        , <&macro_tap &kp RIGHT_MIDDY_KEY>
        , <&macro_param_1to1>
        , <&macro_tap &kp MACRO_PLACEHOLDER>
        ;
    };
    #define RightMiddy(key) RightMiddy_layer0(key)
    #ifdef ENFORCE_BILATERAL
    #define right_middy_layer0_variant right_middy_bilateral
    #else
    #define right_middy_layer0_variant right_middy
    #endif
    #define RightMiddy_layer0(key) right_middy_layer0_variant RIGHT_MIDDY_MOD key
    #ifndef LEFT_INDEX_HOLDING_TYPE
    #define LEFT_INDEX_HOLDING_TYPE INDEX_HOLDING_TYPE
    #endif
    #ifndef LEFT_INDEX_HOLDING_TIME
    #define LEFT_INDEX_HOLDING_TIME INDEX_HOLDING_TIME
    #endif
    #ifndef LEFT_INDEX_STREAK_DECAY
    #define LEFT_INDEX_STREAK_DECAY INDEX_STREAK_DECAY
    #endif
    #ifndef LEFT_INDEX_REPEAT_DECAY
    #define LEFT_INDEX_REPEAT_DECAY INDEX_REPEAT_DECAY
    #endif
    left_index: homey_left_index {
      compatible = "zmk,behavior-hold-tap";
      flavor = LEFT_INDEX_HOLDING_TYPE;
      hold-trigger-key-positions = <RIGHT_HAND_KEYS THUMB_KEYS>;
      hold-trigger-on-release; // wait for other home row mods
      tapping-term-ms = <LEFT_INDEX_HOLDING_TIME>;
      quick-tap-ms = <LEFT_INDEX_REPEAT_DECAY>;
      require-prior-idle-ms = <LEFT_INDEX_STREAK_DECAY>;
      #binding-cells = <2>;
      bindings = <&kp>, <&kp>;
      #ifdef SHIFT_FORGIVENESS
      #if LEFT_INDEX_MOD == LSFT || LEFT_INDEX_MOD == RSFT
      hold-while-undecided; // requires 24.08-beta1 or newer firmware
      retro-tap; // tap on standalone hold
      #endif
      #endif
    };
    left_index_bilateral: homey_left_index_bilateral {
      compatible = "zmk,behavior-hold-tap";
      flavor = LEFT_INDEX_HOLDING_TYPE;
      hold-trigger-key-positions = <RIGHT_HAND_KEYS THUMB_KEYS>;
      hold-trigger-on-release; // wait for other home row mods
      tapping-term-ms = <LEFT_INDEX_HOLDING_TIME>;
      quick-tap-ms = <LEFT_INDEX_REPEAT_DECAY>;
      require-prior-idle-ms = <LEFT_INDEX_STREAK_DECAY>;
      #binding-cells = <2>;
      bindings = <&left_index_hold>, <&kp>;
      #ifdef SHIFT_FORGIVENESS
      #if LEFT_INDEX_MOD == LSFT || LEFT_INDEX_MOD == RSFT
      hold-while-undecided; // requires 24.08-beta1 or newer firmware
      retro-tap; // tap on standalone hold
      #endif
      #endif
    };
    left_index_hold: homey_left_index_hold {
      compatible = "zmk,behavior-macro-one-param";
      wait-ms = <0>;
      tap-ms = <0>;
      #binding-cells = <1>;
      bindings
        = <&macro_param_1to1>
        , <&macro_press &kp MACRO_PLACEHOLDER>
        #ifdef LAYER_LeftIndex
        , <&macro_press &mo LAYER_LeftIndex>
        #endif
        , <&macro_pause_for_release>
        , <&macro_param_1to1>
        , <&macro_release &kp MACRO_PLACEHOLDER>
        #ifdef LAYER_LeftIndex
        , <&macro_release &mo LAYER_LeftIndex>
        #endif
        ;
    };
    left_index_tap: homey_left_index_tap {
      compatible = "zmk,behavior-macro-one-param";
      wait-ms = <0>;
      tap-ms = <0>;
      #binding-cells = <1>;
      bindings
        = <&macro_release
            &kp LSFT &kp RSFT
            &kp LALT &kp RALT
            &kp LCTL &kp RCTL
            &kp LGUI &kp RGUI>
        , <&macro_tap &kp LEFT_INDEX_KEY>
        , <&macro_param_1to1>
        , <&macro_tap &kp MACRO_PLACEHOLDER>
        ;
    };
    #define LeftIndex(key) LeftIndex_layer0(key)
    #ifdef ENFORCE_BILATERAL
    #define left_index_layer0_variant left_index_bilateral
    #else
    #define left_index_layer0_variant left_index
    #endif
    #define LeftIndex_layer0(key) left_index_layer0_variant LEFT_INDEX_MOD key
    #ifndef RIGHT_INDEX_HOLDING_TYPE
    #define RIGHT_INDEX_HOLDING_TYPE INDEX_HOLDING_TYPE
    #endif
    #ifndef RIGHT_INDEX_HOLDING_TIME
    #define RIGHT_INDEX_HOLDING_TIME INDEX_HOLDING_TIME
    #endif
    #ifndef RIGHT_INDEX_STREAK_DECAY
    #define RIGHT_INDEX_STREAK_DECAY INDEX_STREAK_DECAY
    #endif
    #ifndef RIGHT_INDEX_REPEAT_DECAY
    #define RIGHT_INDEX_REPEAT_DECAY INDEX_REPEAT_DECAY
    #endif
    right_index: homey_right_index {
      compatible = "zmk,behavior-hold-tap";
      flavor = RIGHT_INDEX_HOLDING_TYPE;
      hold-trigger-key-positions = <LEFT_HAND_KEYS THUMB_KEYS>;
      hold-trigger-on-release; // wait for other home row mods
      tapping-term-ms = <RIGHT_INDEX_HOLDING_TIME>;
      quick-tap-ms = <RIGHT_INDEX_REPEAT_DECAY>;
      require-prior-idle-ms = <RIGHT_INDEX_STREAK_DECAY>;
      #binding-cells = <2>;
      bindings = <&kp>, <&kp>;
      #ifdef SHIFT_FORGIVENESS
      #if RIGHT_INDEX_MOD == LSFT || RIGHT_INDEX_MOD == RSFT
      hold-while-undecided; // requires 24.08-beta1 or newer firmware
      retro-tap; // tap on standalone hold
      #endif
      #endif
    };
    right_index_bilateral: homey_right_index_bilateral {
      compatible = "zmk,behavior-hold-tap";
      flavor = RIGHT_INDEX_HOLDING_TYPE;
      hold-trigger-key-positions = <LEFT_HAND_KEYS THUMB_KEYS>;
      hold-trigger-on-release; // wait for other home row mods
      tapping-term-ms = <RIGHT_INDEX_HOLDING_TIME>;
      quick-tap-ms = <RIGHT_INDEX_REPEAT_DECAY>;
      require-prior-idle-ms = <RIGHT_INDEX_STREAK_DECAY>;
      #binding-cells = <2>;
      bindings = <&right_index_hold>, <&kp>;
      #ifdef SHIFT_FORGIVENESS
      #if RIGHT_INDEX_MOD == LSFT || RIGHT_INDEX_MOD == RSFT
      hold-while-undecided; // requires 24.08-beta1 or newer firmware
      retro-tap; // tap on standalone hold
      #endif
      #endif
    };
    right_index_hold: homey_right_index_hold {
      compatible = "zmk,behavior-macro-one-param";
      wait-ms = <0>;
      tap-ms = <0>;
      #binding-cells = <1>;
      bindings
        = <&macro_param_1to1>
        , <&macro_press &kp MACRO_PLACEHOLDER>
        #ifdef LAYER_RightIndex
        , <&macro_press &mo LAYER_RightIndex>
        #endif
        , <&macro_pause_for_release>
        , <&macro_param_1to1>
        , <&macro_release &kp MACRO_PLACEHOLDER>
        #ifdef LAYER_RightIndex
        , <&macro_release &mo LAYER_RightIndex>
        #endif
        ;
    };
    right_index_tap: homey_right_index_tap {
      compatible = "zmk,behavior-macro-one-param";
      wait-ms = <0>;
      tap-ms = <0>;
      #binding-cells = <1>;
      bindings
        = <&macro_release
            &kp LSFT &kp RSFT
            &kp LALT &kp RALT
            &kp LCTL &kp RCTL
            &kp LGUI &kp RGUI>
        , <&macro_tap &kp RIGHT_INDEX_KEY>
        , <&macro_param_1to1>
        , <&macro_tap &kp MACRO_PLACEHOLDER>
        ;
    };
    #define RightIndex(key) RightIndex_layer0(key)
    #ifdef ENFORCE_BILATERAL
    #define right_index_layer0_variant right_index_bilateral
    #else
    #define right_index_layer0_variant right_index
    #endif
    #define RightIndex_layer0(key) right_index_layer0_variant RIGHT_INDEX_MOD key
    #ifndef LEFT_RINGY_PINKY_HOLDING_TYPE
    #define LEFT_RINGY_PINKY_HOLDING_TYPE LEFT_RINGY_CHORD_HOLDING_TYPE
    #endif
    #ifndef LEFT_RINGY_PINKY_HOLDING_TIME
    #define LEFT_RINGY_PINKY_HOLDING_TIME LEFT_RINGY_CHORD_HOLDING_TIME
    #endif
    #ifndef LEFT_RINGY_PINKY_STREAK_DECAY
    #define LEFT_RINGY_PINKY_STREAK_DECAY LEFT_RINGY_CHORD_STREAK_DECAY
    #endif
    #ifndef LEFT_RINGY_PINKY_REPEAT_DECAY
    #define LEFT_RINGY_PINKY_REPEAT_DECAY LEFT_RINGY_CHORD_REPEAT_DECAY
    #endif
    left_ringy_pinky: homey_left_ringy_pinky {
      compatible = "zmk,behavior-hold-tap";
      flavor = LEFT_RINGY_HOLDING_TYPE;
      hold-trigger-key-positions = <RIGHT_HAND_KEYS THUMB_KEYS>;
      hold-trigger-on-release; // wait for other home row mods
      tapping-term-ms = <LEFT_RINGY_HOLDING_TIME>;
      quick-tap-ms = <LEFT_RINGY_REPEAT_DECAY>;
      require-prior-idle-ms = <LEFT_RINGY_STREAK_DECAY>;
      #binding-cells = <2>;
      bindings = <&kp>, <&kp>;
    };
    left_ringy_pinky_bilateral: homey_left_ringy_pinky_bilateral {
      compatible = "zmk,behavior-hold-tap";
      flavor = LEFT_RINGY_HOLDING_TYPE;
      hold-trigger-key-positions = <RIGHT_HAND_KEYS THUMB_KEYS>;
      hold-trigger-on-release; // wait for other home row mods
      tapping-term-ms = <LEFT_RINGY_HOLDING_TIME>;
      quick-tap-ms = <LEFT_RINGY_REPEAT_DECAY>;
      require-prior-idle-ms = <LEFT_RINGY_STREAK_DECAY>;
      #binding-cells = <2>;
      bindings = <&kp>, <&left_ringy_tap>;
    };
    #define LeftRingyPinky left_ringy_pinky_bilateral LEFT_PINKY_MOD LEFT_PINKY_KEY
    #ifndef LEFT_MIDDY_PINKY_HOLDING_TYPE
    #define LEFT_MIDDY_PINKY_HOLDING_TYPE LEFT_MIDDY_CHORD_HOLDING_TYPE
    #endif
    #ifndef LEFT_MIDDY_PINKY_HOLDING_TIME
    #define LEFT_MIDDY_PINKY_HOLDING_TIME LEFT_MIDDY_CHORD_HOLDING_TIME
    #endif
    #ifndef LEFT_MIDDY_PINKY_STREAK_DECAY
    #define LEFT_MIDDY_PINKY_STREAK_DECAY LEFT_MIDDY_CHORD_STREAK_DECAY
    #endif
    #ifndef LEFT_MIDDY_PINKY_REPEAT_DECAY
    #define LEFT_MIDDY_PINKY_REPEAT_DECAY LEFT_MIDDY_CHORD_REPEAT_DECAY
    #endif
    left_middy_pinky: homey_left_middy_pinky {
      compatible = "zmk,behavior-hold-tap";
      flavor = LEFT_MIDDY_HOLDING_TYPE;
      hold-trigger-key-positions = <RIGHT_HAND_KEYS THUMB_KEYS>;
      hold-trigger-on-release; // wait for other home row mods
      tapping-term-ms = <LEFT_MIDDY_HOLDING_TIME>;
      quick-tap-ms = <LEFT_MIDDY_REPEAT_DECAY>;
      require-prior-idle-ms = <LEFT_MIDDY_STREAK_DECAY>;
      #binding-cells = <2>;
      bindings = <&kp>, <&kp>;
    };
    left_middy_pinky_bilateral: homey_left_middy_pinky_bilateral {
      compatible = "zmk,behavior-hold-tap";
      flavor = LEFT_MIDDY_HOLDING_TYPE;
      hold-trigger-key-positions = <RIGHT_HAND_KEYS THUMB_KEYS>;
      hold-trigger-on-release; // wait for other home row mods
      tapping-term-ms = <LEFT_MIDDY_HOLDING_TIME>;
      quick-tap-ms = <LEFT_MIDDY_REPEAT_DECAY>;
      require-prior-idle-ms = <LEFT_MIDDY_STREAK_DECAY>;
      #binding-cells = <2>;
      bindings = <&kp>, <&left_middy_tap>;
    };
    #define LeftMiddyPinky left_middy_pinky_bilateral LEFT_PINKY_MOD LEFT_PINKY_KEY
    #ifndef LEFT_INDEX_PINKY_HOLDING_TYPE
    #define LEFT_INDEX_PINKY_HOLDING_TYPE LEFT_INDEX_CHORD_HOLDING_TYPE
    #endif
    #ifndef LEFT_INDEX_PINKY_HOLDING_TIME
    #define LEFT_INDEX_PINKY_HOLDING_TIME LEFT_INDEX_CHORD_HOLDING_TIME
    #endif
    #ifndef LEFT_INDEX_PINKY_STREAK_DECAY
    #define LEFT_INDEX_PINKY_STREAK_DECAY LEFT_INDEX_CHORD_STREAK_DECAY
    #endif
    #ifndef LEFT_INDEX_PINKY_REPEAT_DECAY
    #define LEFT_INDEX_PINKY_REPEAT_DECAY LEFT_INDEX_CHORD_REPEAT_DECAY
    #endif
    left_index_pinky: homey_left_index_pinky {
      compatible = "zmk,behavior-hold-tap";
      flavor = LEFT_INDEX_HOLDING_TYPE;
      hold-trigger-key-positions = <RIGHT_HAND_KEYS THUMB_KEYS>;
      hold-trigger-on-release; // wait for other home row mods
      tapping-term-ms = <LEFT_INDEX_HOLDING_TIME>;
      quick-tap-ms = <LEFT_INDEX_REPEAT_DECAY>;
      require-prior-idle-ms = <LEFT_INDEX_STREAK_DECAY>;
      #binding-cells = <2>;
      bindings = <&kp>, <&kp>;
    };
    left_index_pinky_bilateral: homey_left_index_pinky_bilateral {
      compatible = "zmk,behavior-hold-tap";
      flavor = LEFT_INDEX_HOLDING_TYPE;
      hold-trigger-key-positions = <RIGHT_HAND_KEYS THUMB_KEYS>;
      hold-trigger-on-release; // wait for other home row mods
      tapping-term-ms = <LEFT_INDEX_HOLDING_TIME>;
      quick-tap-ms = <LEFT_INDEX_REPEAT_DECAY>;
      require-prior-idle-ms = <LEFT_INDEX_STREAK_DECAY>;
      #binding-cells = <2>;
      bindings = <&kp>, <&left_index_tap>;
    };
    #define LeftIndexPinky left_index_pinky_bilateral LEFT_PINKY_MOD LEFT_PINKY_KEY
    #ifndef RIGHT_RINGY_PINKY_HOLDING_TYPE
    #define RIGHT_RINGY_PINKY_HOLDING_TYPE RIGHT_RINGY_CHORD_HOLDING_TYPE
    #endif
    #ifndef RIGHT_RINGY_PINKY_HOLDING_TIME
    #define RIGHT_RINGY_PINKY_HOLDING_TIME RIGHT_RINGY_CHORD_HOLDING_TIME
    #endif
    #ifndef RIGHT_RINGY_PINKY_STREAK_DECAY
    #define RIGHT_RINGY_PINKY_STREAK_DECAY RIGHT_RINGY_CHORD_STREAK_DECAY
    #endif
    #ifndef RIGHT_RINGY_PINKY_REPEAT_DECAY
    #define RIGHT_RINGY_PINKY_REPEAT_DECAY RIGHT_RINGY_CHORD_REPEAT_DECAY
    #endif
    right_ringy_pinky: homey_right_ringy_pinky {
      compatible = "zmk,behavior-hold-tap";
      flavor = RIGHT_RINGY_HOLDING_TYPE;
      hold-trigger-key-positions = <LEFT_HAND_KEYS THUMB_KEYS>;
      hold-trigger-on-release; // wait for other home row mods
      tapping-term-ms = <RIGHT_RINGY_HOLDING_TIME>;
      quick-tap-ms = <RIGHT_RINGY_REPEAT_DECAY>;
      require-prior-idle-ms = <RIGHT_RINGY_STREAK_DECAY>;
      #binding-cells = <2>;
      bindings = <&kp>, <&kp>;
    };
    right_ringy_pinky_bilateral: homey_right_ringy_pinky_bilateral {
      compatible = "zmk,behavior-hold-tap";
      flavor = RIGHT_RINGY_HOLDING_TYPE;
      hold-trigger-key-positions = <LEFT_HAND_KEYS THUMB_KEYS>;
      hold-trigger-on-release; // wait for other home row mods
      tapping-term-ms = <RIGHT_RINGY_HOLDING_TIME>;
      quick-tap-ms = <RIGHT_RINGY_REPEAT_DECAY>;
      require-prior-idle-ms = <RIGHT_RINGY_STREAK_DECAY>;
      #binding-cells = <2>;
      bindings = <&kp>, <&right_ringy_tap>;
    };
    #define RightRingyPinky right_ringy_pinky_bilateral RIGHT_PINKY_MOD RIGHT_PINKY_KEY
    #ifndef RIGHT_MIDDY_PINKY_HOLDING_TYPE
    #define RIGHT_MIDDY_PINKY_HOLDING_TYPE RIGHT_MIDDY_CHORD_HOLDING_TYPE
    #endif
    #ifndef RIGHT_MIDDY_PINKY_HOLDING_TIME
    #define RIGHT_MIDDY_PINKY_HOLDING_TIME RIGHT_MIDDY_CHORD_HOLDING_TIME
    #endif
    #ifndef RIGHT_MIDDY_PINKY_STREAK_DECAY
    #define RIGHT_MIDDY_PINKY_STREAK_DECAY RIGHT_MIDDY_CHORD_STREAK_DECAY
    #endif
    #ifndef RIGHT_MIDDY_PINKY_REPEAT_DECAY
    #define RIGHT_MIDDY_PINKY_REPEAT_DECAY RIGHT_MIDDY_CHORD_REPEAT_DECAY
    #endif
    right_middy_pinky: homey_right_middy_pinky {
      compatible = "zmk,behavior-hold-tap";
      flavor = RIGHT_MIDDY_HOLDING_TYPE;
      hold-trigger-key-positions = <LEFT_HAND_KEYS THUMB_KEYS>;
      hold-trigger-on-release; // wait for other home row mods
      tapping-term-ms = <RIGHT_MIDDY_HOLDING_TIME>;
      quick-tap-ms = <RIGHT_MIDDY_REPEAT_DECAY>;
      require-prior-idle-ms = <RIGHT_MIDDY_STREAK_DECAY>;
      #binding-cells = <2>;
      bindings = <&kp>, <&kp>;
    };
    right_middy_pinky_bilateral: homey_right_middy_pinky_bilateral {
      compatible = "zmk,behavior-hold-tap";
      flavor = RIGHT_MIDDY_HOLDING_TYPE;
      hold-trigger-key-positions = <LEFT_HAND_KEYS THUMB_KEYS>;
      hold-trigger-on-release; // wait for other home row mods
      tapping-term-ms = <RIGHT_MIDDY_HOLDING_TIME>;
      quick-tap-ms = <RIGHT_MIDDY_REPEAT_DECAY>;
      require-prior-idle-ms = <RIGHT_MIDDY_STREAK_DECAY>;
      #binding-cells = <2>;
      bindings = <&kp>, <&right_middy_tap>;
    };
    #define RightMiddyPinky right_middy_pinky_bilateral RIGHT_PINKY_MOD RIGHT_PINKY_KEY
    #ifndef RIGHT_INDEX_PINKY_HOLDING_TYPE
    #define RIGHT_INDEX_PINKY_HOLDING_TYPE RIGHT_INDEX_CHORD_HOLDING_TYPE
    #endif
    #ifndef RIGHT_INDEX_PINKY_HOLDING_TIME
    #define RIGHT_INDEX_PINKY_HOLDING_TIME RIGHT_INDEX_CHORD_HOLDING_TIME
    #endif
    #ifndef RIGHT_INDEX_PINKY_STREAK_DECAY
    #define RIGHT_INDEX_PINKY_STREAK_DECAY RIGHT_INDEX_CHORD_STREAK_DECAY
    #endif
    #ifndef RIGHT_INDEX_PINKY_REPEAT_DECAY
    #define RIGHT_INDEX_PINKY_REPEAT_DECAY RIGHT_INDEX_CHORD_REPEAT_DECAY
    #endif
    right_index_pinky: homey_right_index_pinky {
      compatible = "zmk,behavior-hold-tap";
      flavor = RIGHT_INDEX_HOLDING_TYPE;
      hold-trigger-key-positions = <LEFT_HAND_KEYS THUMB_KEYS>;
      hold-trigger-on-release; // wait for other home row mods
      tapping-term-ms = <RIGHT_INDEX_HOLDING_TIME>;
      quick-tap-ms = <RIGHT_INDEX_REPEAT_DECAY>;
      require-prior-idle-ms = <RIGHT_INDEX_STREAK_DECAY>;
      #binding-cells = <2>;
      bindings = <&kp>, <&kp>;
    };
    right_index_pinky_bilateral: homey_right_index_pinky_bilateral {
      compatible = "zmk,behavior-hold-tap";
      flavor = RIGHT_INDEX_HOLDING_TYPE;
      hold-trigger-key-positions = <LEFT_HAND_KEYS THUMB_KEYS>;
      hold-trigger-on-release; // wait for other home row mods
      tapping-term-ms = <RIGHT_INDEX_HOLDING_TIME>;
      quick-tap-ms = <RIGHT_INDEX_REPEAT_DECAY>;
      require-prior-idle-ms = <RIGHT_INDEX_STREAK_DECAY>;
      #binding-cells = <2>;
      bindings = <&kp>, <&right_index_tap>;
    };
    #define RightIndexPinky right_index_pinky_bilateral RIGHT_PINKY_MOD RIGHT_PINKY_KEY
    #ifndef LEFT_PINKY_RINGY_HOLDING_TYPE
    #define LEFT_PINKY_RINGY_HOLDING_TYPE LEFT_PINKY_CHORD_HOLDING_TYPE
    #endif
    #ifndef LEFT_PINKY_RINGY_HOLDING_TIME
    #define LEFT_PINKY_RINGY_HOLDING_TIME LEFT_PINKY_CHORD_HOLDING_TIME
    #endif
    #ifndef LEFT_PINKY_RINGY_STREAK_DECAY
    #define LEFT_PINKY_RINGY_STREAK_DECAY LEFT_PINKY_CHORD_STREAK_DECAY
    #endif
    #ifndef LEFT_PINKY_RINGY_REPEAT_DECAY
    #define LEFT_PINKY_RINGY_REPEAT_DECAY LEFT_PINKY_CHORD_REPEAT_DECAY
    #endif
    left_pinky_ringy: homey_left_pinky_ringy {
      compatible = "zmk,behavior-hold-tap";
      flavor = LEFT_PINKY_HOLDING_TYPE;
      hold-trigger-key-positions = <RIGHT_HAND_KEYS THUMB_KEYS>;
      hold-trigger-on-release; // wait for other home row mods
      tapping-term-ms = <LEFT_PINKY_HOLDING_TIME>;
      quick-tap-ms = <LEFT_PINKY_REPEAT_DECAY>;
      require-prior-idle-ms = <LEFT_PINKY_STREAK_DECAY>;
      #binding-cells = <2>;
      bindings = <&kp>, <&kp>;
    };
    left_pinky_ringy_bilateral: homey_left_pinky_ringy_bilateral {
      compatible = "zmk,behavior-hold-tap";
      flavor = LEFT_PINKY_HOLDING_TYPE;
      hold-trigger-key-positions = <RIGHT_HAND_KEYS THUMB_KEYS>;
      hold-trigger-on-release; // wait for other home row mods
      tapping-term-ms = <LEFT_PINKY_HOLDING_TIME>;
      quick-tap-ms = <LEFT_PINKY_REPEAT_DECAY>;
      require-prior-idle-ms = <LEFT_PINKY_STREAK_DECAY>;
      #binding-cells = <2>;
      bindings = <&kp>, <&left_pinky_tap>;
    };
    #define LeftPinkyRingy left_pinky_ringy_bilateral LEFT_RINGY_MOD LEFT_RINGY_KEY
    #ifndef LEFT_MIDDY_RINGY_HOLDING_TYPE
    #define LEFT_MIDDY_RINGY_HOLDING_TYPE LEFT_MIDDY_CHORD_HOLDING_TYPE
    #endif
    #ifndef LEFT_MIDDY_RINGY_HOLDING_TIME
    #define LEFT_MIDDY_RINGY_HOLDING_TIME LEFT_MIDDY_CHORD_HOLDING_TIME
    #endif
    #ifndef LEFT_MIDDY_RINGY_STREAK_DECAY
    #define LEFT_MIDDY_RINGY_STREAK_DECAY LEFT_MIDDY_CHORD_STREAK_DECAY
    #endif
    #ifndef LEFT_MIDDY_RINGY_REPEAT_DECAY
    #define LEFT_MIDDY_RINGY_REPEAT_DECAY LEFT_MIDDY_CHORD_REPEAT_DECAY
    #endif
    left_middy_ringy: homey_left_middy_ringy {
      compatible = "zmk,behavior-hold-tap";
      flavor = LEFT_MIDDY_HOLDING_TYPE;
      hold-trigger-key-positions = <RIGHT_HAND_KEYS THUMB_KEYS>;
      hold-trigger-on-release; // wait for other home row mods
      tapping-term-ms = <LEFT_MIDDY_HOLDING_TIME>;
      quick-tap-ms = <LEFT_MIDDY_REPEAT_DECAY>;
      require-prior-idle-ms = <LEFT_MIDDY_STREAK_DECAY>;
      #binding-cells = <2>;
      bindings = <&kp>, <&kp>;
    };
    left_middy_ringy_bilateral: homey_left_middy_ringy_bilateral {
      compatible = "zmk,behavior-hold-tap";
      flavor = LEFT_MIDDY_HOLDING_TYPE;
      hold-trigger-key-positions = <RIGHT_HAND_KEYS THUMB_KEYS>;
      hold-trigger-on-release; // wait for other home row mods
      tapping-term-ms = <LEFT_MIDDY_HOLDING_TIME>;
      quick-tap-ms = <LEFT_MIDDY_REPEAT_DECAY>;
      require-prior-idle-ms = <LEFT_MIDDY_STREAK_DECAY>;
      #binding-cells = <2>;
      bindings = <&kp>, <&left_middy_tap>;
    };
    #define LeftMiddyRingy left_middy_ringy_bilateral LEFT_RINGY_MOD LEFT_RINGY_KEY
    #ifndef LEFT_INDEX_RINGY_HOLDING_TYPE
    #define LEFT_INDEX_RINGY_HOLDING_TYPE LEFT_INDEX_CHORD_HOLDING_TYPE
    #endif
    #ifndef LEFT_INDEX_RINGY_HOLDING_TIME
    #define LEFT_INDEX_RINGY_HOLDING_TIME LEFT_INDEX_CHORD_HOLDING_TIME
    #endif
    #ifndef LEFT_INDEX_RINGY_STREAK_DECAY
    #define LEFT_INDEX_RINGY_STREAK_DECAY LEFT_INDEX_CHORD_STREAK_DECAY
    #endif
    #ifndef LEFT_INDEX_RINGY_REPEAT_DECAY
    #define LEFT_INDEX_RINGY_REPEAT_DECAY LEFT_INDEX_CHORD_REPEAT_DECAY
    #endif
    left_index_ringy: homey_left_index_ringy {
      compatible = "zmk,behavior-hold-tap";
      flavor = LEFT_INDEX_HOLDING_TYPE;
      hold-trigger-key-positions = <RIGHT_HAND_KEYS THUMB_KEYS>;
      hold-trigger-on-release; // wait for other home row mods
      tapping-term-ms = <LEFT_INDEX_HOLDING_TIME>;
      quick-tap-ms = <LEFT_INDEX_REPEAT_DECAY>;
      require-prior-idle-ms = <LEFT_INDEX_STREAK_DECAY>;
      #binding-cells = <2>;
      bindings = <&kp>, <&kp>;
    };
    left_index_ringy_bilateral: homey_left_index_ringy_bilateral {
      compatible = "zmk,behavior-hold-tap";
      flavor = LEFT_INDEX_HOLDING_TYPE;
      hold-trigger-key-positions = <RIGHT_HAND_KEYS THUMB_KEYS>;
      hold-trigger-on-release; // wait for other home row mods
      tapping-term-ms = <LEFT_INDEX_HOLDING_TIME>;
      quick-tap-ms = <LEFT_INDEX_REPEAT_DECAY>;
      require-prior-idle-ms = <LEFT_INDEX_STREAK_DECAY>;
      #binding-cells = <2>;
      bindings = <&kp>, <&left_index_tap>;
    };
    #define LeftIndexRingy left_index_ringy_bilateral LEFT_RINGY_MOD LEFT_RINGY_KEY
    #ifndef RIGHT_PINKY_RINGY_HOLDING_TYPE
    #define RIGHT_PINKY_RINGY_HOLDING_TYPE RIGHT_PINKY_CHORD_HOLDING_TYPE
    #endif
    #ifndef RIGHT_PINKY_RINGY_HOLDING_TIME
    #define RIGHT_PINKY_RINGY_HOLDING_TIME RIGHT_PINKY_CHORD_HOLDING_TIME
    #endif
    #ifndef RIGHT_PINKY_RINGY_STREAK_DECAY
    #define RIGHT_PINKY_RINGY_STREAK_DECAY RIGHT_PINKY_CHORD_STREAK_DECAY
    #endif
    #ifndef RIGHT_PINKY_RINGY_REPEAT_DECAY
    #define RIGHT_PINKY_RINGY_REPEAT_DECAY RIGHT_PINKY_CHORD_REPEAT_DECAY
    #endif
    right_pinky_ringy: homey_right_pinky_ringy {
      compatible = "zmk,behavior-hold-tap";
      flavor = RIGHT_PINKY_HOLDING_TYPE;
      hold-trigger-key-positions = <LEFT_HAND_KEYS THUMB_KEYS>;
      hold-trigger-on-release; // wait for other home row mods
      tapping-term-ms = <RIGHT_PINKY_HOLDING_TIME>;
      quick-tap-ms = <RIGHT_PINKY_REPEAT_DECAY>;
      require-prior-idle-ms = <RIGHT_PINKY_STREAK_DECAY>;
      #binding-cells = <2>;
      bindings = <&kp>, <&kp>;
    };
    right_pinky_ringy_bilateral: homey_right_pinky_ringy_bilateral {
      compatible = "zmk,behavior-hold-tap";
      flavor = RIGHT_PINKY_HOLDING_TYPE;
      hold-trigger-key-positions = <LEFT_HAND_KEYS THUMB_KEYS>;
      hold-trigger-on-release; // wait for other home row mods
      tapping-term-ms = <RIGHT_PINKY_HOLDING_TIME>;
      quick-tap-ms = <RIGHT_PINKY_REPEAT_DECAY>;
      require-prior-idle-ms = <RIGHT_PINKY_STREAK_DECAY>;
      #binding-cells = <2>;
      bindings = <&kp>, <&right_pinky_tap>;
    };
    #define RightPinkyRingy right_pinky_ringy_bilateral RIGHT_RINGY_MOD RIGHT_RINGY_KEY
    #ifndef RIGHT_MIDDY_RINGY_HOLDING_TYPE
    #define RIGHT_MIDDY_RINGY_HOLDING_TYPE RIGHT_MIDDY_CHORD_HOLDING_TYPE
    #endif
    #ifndef RIGHT_MIDDY_RINGY_HOLDING_TIME
    #define RIGHT_MIDDY_RINGY_HOLDING_TIME RIGHT_MIDDY_CHORD_HOLDING_TIME
    #endif
    #ifndef RIGHT_MIDDY_RINGY_STREAK_DECAY
    #define RIGHT_MIDDY_RINGY_STREAK_DECAY RIGHT_MIDDY_CHORD_STREAK_DECAY
    #endif
    #ifndef RIGHT_MIDDY_RINGY_REPEAT_DECAY
    #define RIGHT_MIDDY_RINGY_REPEAT_DECAY RIGHT_MIDDY_CHORD_REPEAT_DECAY
    #endif
    right_middy_ringy: homey_right_middy_ringy {
      compatible = "zmk,behavior-hold-tap";
      flavor = RIGHT_MIDDY_HOLDING_TYPE;
      hold-trigger-key-positions = <LEFT_HAND_KEYS THUMB_KEYS>;
      hold-trigger-on-release; // wait for other home row mods
      tapping-term-ms = <RIGHT_MIDDY_HOLDING_TIME>;
      quick-tap-ms = <RIGHT_MIDDY_REPEAT_DECAY>;
      require-prior-idle-ms = <RIGHT_MIDDY_STREAK_DECAY>;
      #binding-cells = <2>;
      bindings = <&kp>, <&kp>;
    };
    right_middy_ringy_bilateral: homey_right_middy_ringy_bilateral {
      compatible = "zmk,behavior-hold-tap";
      flavor = RIGHT_MIDDY_HOLDING_TYPE;
      hold-trigger-key-positions = <LEFT_HAND_KEYS THUMB_KEYS>;
      hold-trigger-on-release; // wait for other home row mods
      tapping-term-ms = <RIGHT_MIDDY_HOLDING_TIME>;
      quick-tap-ms = <RIGHT_MIDDY_REPEAT_DECAY>;
      require-prior-idle-ms = <RIGHT_MIDDY_STREAK_DECAY>;
      #binding-cells = <2>;
      bindings = <&kp>, <&right_middy_tap>;
    };
    #define RightMiddyRingy right_middy_ringy_bilateral RIGHT_RINGY_MOD RIGHT_RINGY_KEY
    #ifndef RIGHT_INDEX_RINGY_HOLDING_TYPE
    #define RIGHT_INDEX_RINGY_HOLDING_TYPE RIGHT_INDEX_CHORD_HOLDING_TYPE
    #endif
    #ifndef RIGHT_INDEX_RINGY_HOLDING_TIME
    #define RIGHT_INDEX_RINGY_HOLDING_TIME RIGHT_INDEX_CHORD_HOLDING_TIME
    #endif
    #ifndef RIGHT_INDEX_RINGY_STREAK_DECAY
    #define RIGHT_INDEX_RINGY_STREAK_DECAY RIGHT_INDEX_CHORD_STREAK_DECAY
    #endif
    #ifndef RIGHT_INDEX_RINGY_REPEAT_DECAY
    #define RIGHT_INDEX_RINGY_REPEAT_DECAY RIGHT_INDEX_CHORD_REPEAT_DECAY
    #endif
    right_index_ringy: homey_right_index_ringy {
      compatible = "zmk,behavior-hold-tap";
      flavor = RIGHT_INDEX_HOLDING_TYPE;
      hold-trigger-key-positions = <LEFT_HAND_KEYS THUMB_KEYS>;
      hold-trigger-on-release; // wait for other home row mods
      tapping-term-ms = <RIGHT_INDEX_HOLDING_TIME>;
      quick-tap-ms = <RIGHT_INDEX_REPEAT_DECAY>;
      require-prior-idle-ms = <RIGHT_INDEX_STREAK_DECAY>;
      #binding-cells = <2>;
      bindings = <&kp>, <&kp>;
    };
    right_index_ringy_bilateral: homey_right_index_ringy_bilateral {
      compatible = "zmk,behavior-hold-tap";
      flavor = RIGHT_INDEX_HOLDING_TYPE;
      hold-trigger-key-positions = <LEFT_HAND_KEYS THUMB_KEYS>;
      hold-trigger-on-release; // wait for other home row mods
      tapping-term-ms = <RIGHT_INDEX_HOLDING_TIME>;
      quick-tap-ms = <RIGHT_INDEX_REPEAT_DECAY>;
      require-prior-idle-ms = <RIGHT_INDEX_STREAK_DECAY>;
      #binding-cells = <2>;
      bindings = <&kp>, <&right_index_tap>;
    };
    #define RightIndexRingy right_index_ringy_bilateral RIGHT_RINGY_MOD RIGHT_RINGY_KEY
    #ifndef LEFT_PINKY_MIDDY_HOLDING_TYPE
    #define LEFT_PINKY_MIDDY_HOLDING_TYPE LEFT_PINKY_CHORD_HOLDING_TYPE
    #endif
    #ifndef LEFT_PINKY_MIDDY_HOLDING_TIME
    #define LEFT_PINKY_MIDDY_HOLDING_TIME LEFT_PINKY_CHORD_HOLDING_TIME
    #endif
    #ifndef LEFT_PINKY_MIDDY_STREAK_DECAY
    #define LEFT_PINKY_MIDDY_STREAK_DECAY LEFT_PINKY_CHORD_STREAK_DECAY
    #endif
    #ifndef LEFT_PINKY_MIDDY_REPEAT_DECAY
    #define LEFT_PINKY_MIDDY_REPEAT_DECAY LEFT_PINKY_CHORD_REPEAT_DECAY
    #endif
    left_pinky_middy: homey_left_pinky_middy {
      compatible = "zmk,behavior-hold-tap";
      flavor = LEFT_PINKY_HOLDING_TYPE;
      hold-trigger-key-positions = <RIGHT_HAND_KEYS THUMB_KEYS>;
      hold-trigger-on-release; // wait for other home row mods
      tapping-term-ms = <LEFT_PINKY_HOLDING_TIME>;
      quick-tap-ms = <LEFT_PINKY_REPEAT_DECAY>;
      require-prior-idle-ms = <LEFT_PINKY_STREAK_DECAY>;
      #binding-cells = <2>;
      bindings = <&kp>, <&kp>;
    };
    left_pinky_middy_bilateral: homey_left_pinky_middy_bilateral {
      compatible = "zmk,behavior-hold-tap";
      flavor = LEFT_PINKY_HOLDING_TYPE;
      hold-trigger-key-positions = <RIGHT_HAND_KEYS THUMB_KEYS>;
      hold-trigger-on-release; // wait for other home row mods
      tapping-term-ms = <LEFT_PINKY_HOLDING_TIME>;
      quick-tap-ms = <LEFT_PINKY_REPEAT_DECAY>;
      require-prior-idle-ms = <LEFT_PINKY_STREAK_DECAY>;
      #binding-cells = <2>;
      bindings = <&kp>, <&left_pinky_tap>;
    };
    #define LeftPinkyMiddy left_pinky_middy_bilateral LEFT_MIDDY_MOD LEFT_MIDDY_KEY
    #ifndef LEFT_RINGY_MIDDY_HOLDING_TYPE
    #define LEFT_RINGY_MIDDY_HOLDING_TYPE LEFT_RINGY_CHORD_HOLDING_TYPE
    #endif
    #ifndef LEFT_RINGY_MIDDY_HOLDING_TIME
    #define LEFT_RINGY_MIDDY_HOLDING_TIME LEFT_RINGY_CHORD_HOLDING_TIME
    #endif
    #ifndef LEFT_RINGY_MIDDY_STREAK_DECAY
    #define LEFT_RINGY_MIDDY_STREAK_DECAY LEFT_RINGY_CHORD_STREAK_DECAY
    #endif
    #ifndef LEFT_RINGY_MIDDY_REPEAT_DECAY
    #define LEFT_RINGY_MIDDY_REPEAT_DECAY LEFT_RINGY_CHORD_REPEAT_DECAY
    #endif
    left_ringy_middy: homey_left_ringy_middy {
      compatible = "zmk,behavior-hold-tap";
      flavor = LEFT_RINGY_HOLDING_TYPE;
      hold-trigger-key-positions = <RIGHT_HAND_KEYS THUMB_KEYS>;
      hold-trigger-on-release; // wait for other home row mods
      tapping-term-ms = <LEFT_RINGY_HOLDING_TIME>;
      quick-tap-ms = <LEFT_RINGY_REPEAT_DECAY>;
      require-prior-idle-ms = <LEFT_RINGY_STREAK_DECAY>;
      #binding-cells = <2>;
      bindings = <&kp>, <&kp>;
    };
    left_ringy_middy_bilateral: homey_left_ringy_middy_bilateral {
      compatible = "zmk,behavior-hold-tap";
      flavor = LEFT_RINGY_HOLDING_TYPE;
      hold-trigger-key-positions = <RIGHT_HAND_KEYS THUMB_KEYS>;
      hold-trigger-on-release; // wait for other home row mods
      tapping-term-ms = <LEFT_RINGY_HOLDING_TIME>;
      quick-tap-ms = <LEFT_RINGY_REPEAT_DECAY>;
      require-prior-idle-ms = <LEFT_RINGY_STREAK_DECAY>;
      #binding-cells = <2>;
      bindings = <&kp>, <&left_ringy_tap>;
    };
    #define LeftRingyMiddy left_ringy_middy_bilateral LEFT_MIDDY_MOD LEFT_MIDDY_KEY
    #ifndef LEFT_INDEX_MIDDY_HOLDING_TYPE
    #define LEFT_INDEX_MIDDY_HOLDING_TYPE LEFT_INDEX_CHORD_HOLDING_TYPE
    #endif
    #ifndef LEFT_INDEX_MIDDY_HOLDING_TIME
    #define LEFT_INDEX_MIDDY_HOLDING_TIME LEFT_INDEX_CHORD_HOLDING_TIME
    #endif
    #ifndef LEFT_INDEX_MIDDY_STREAK_DECAY
    #define LEFT_INDEX_MIDDY_STREAK_DECAY LEFT_INDEX_CHORD_STREAK_DECAY
    #endif
    #ifndef LEFT_INDEX_MIDDY_REPEAT_DECAY
    #define LEFT_INDEX_MIDDY_REPEAT_DECAY LEFT_INDEX_CHORD_REPEAT_DECAY
    #endif
    left_index_middy: homey_left_index_middy {
      compatible = "zmk,behavior-hold-tap";
      flavor = LEFT_INDEX_HOLDING_TYPE;
      hold-trigger-key-positions = <RIGHT_HAND_KEYS THUMB_KEYS>;
      hold-trigger-on-release; // wait for other home row mods
      tapping-term-ms = <LEFT_INDEX_HOLDING_TIME>;
      quick-tap-ms = <LEFT_INDEX_REPEAT_DECAY>;
      require-prior-idle-ms = <LEFT_INDEX_STREAK_DECAY>;
      #binding-cells = <2>;
      bindings = <&kp>, <&kp>;
    };
    left_index_middy_bilateral: homey_left_index_middy_bilateral {
      compatible = "zmk,behavior-hold-tap";
      flavor = LEFT_INDEX_HOLDING_TYPE;
      hold-trigger-key-positions = <RIGHT_HAND_KEYS THUMB_KEYS>;
      hold-trigger-on-release; // wait for other home row mods
      tapping-term-ms = <LEFT_INDEX_HOLDING_TIME>;
      quick-tap-ms = <LEFT_INDEX_REPEAT_DECAY>;
      require-prior-idle-ms = <LEFT_INDEX_STREAK_DECAY>;
      #binding-cells = <2>;
      bindings = <&kp>, <&left_index_tap>;
    };
    #define LeftIndexMiddy left_index_middy_bilateral LEFT_MIDDY_MOD LEFT_MIDDY_KEY
    #ifndef RIGHT_PINKY_MIDDY_HOLDING_TYPE
    #define RIGHT_PINKY_MIDDY_HOLDING_TYPE RIGHT_PINKY_CHORD_HOLDING_TYPE
    #endif
    #ifndef RIGHT_PINKY_MIDDY_HOLDING_TIME
    #define RIGHT_PINKY_MIDDY_HOLDING_TIME RIGHT_PINKY_CHORD_HOLDING_TIME
    #endif
    #ifndef RIGHT_PINKY_MIDDY_STREAK_DECAY
    #define RIGHT_PINKY_MIDDY_STREAK_DECAY RIGHT_PINKY_CHORD_STREAK_DECAY
    #endif
    #ifndef RIGHT_PINKY_MIDDY_REPEAT_DECAY
    #define RIGHT_PINKY_MIDDY_REPEAT_DECAY RIGHT_PINKY_CHORD_REPEAT_DECAY
    #endif
    right_pinky_middy: homey_right_pinky_middy {
      compatible = "zmk,behavior-hold-tap";
      flavor = RIGHT_PINKY_HOLDING_TYPE;
      hold-trigger-key-positions = <LEFT_HAND_KEYS THUMB_KEYS>;
      hold-trigger-on-release; // wait for other home row mods
      tapping-term-ms = <RIGHT_PINKY_HOLDING_TIME>;
      quick-tap-ms = <RIGHT_PINKY_REPEAT_DECAY>;
      require-prior-idle-ms = <RIGHT_PINKY_STREAK_DECAY>;
      #binding-cells = <2>;
      bindings = <&kp>, <&kp>;
    };
    right_pinky_middy_bilateral: homey_right_pinky_middy_bilateral {
      compatible = "zmk,behavior-hold-tap";
      flavor = RIGHT_PINKY_HOLDING_TYPE;
      hold-trigger-key-positions = <LEFT_HAND_KEYS THUMB_KEYS>;
      hold-trigger-on-release; // wait for other home row mods
      tapping-term-ms = <RIGHT_PINKY_HOLDING_TIME>;
      quick-tap-ms = <RIGHT_PINKY_REPEAT_DECAY>;
      require-prior-idle-ms = <RIGHT_PINKY_STREAK_DECAY>;
      #binding-cells = <2>;
      bindings = <&kp>, <&right_pinky_tap>;
    };
    #define RightPinkyMiddy right_pinky_middy_bilateral RIGHT_MIDDY_MOD RIGHT_MIDDY_KEY
    #ifndef RIGHT_RINGY_MIDDY_HOLDING_TYPE
    #define RIGHT_RINGY_MIDDY_HOLDING_TYPE RIGHT_RINGY_CHORD_HOLDING_TYPE
    #endif
    #ifndef RIGHT_RINGY_MIDDY_HOLDING_TIME
    #define RIGHT_RINGY_MIDDY_HOLDING_TIME RIGHT_RINGY_CHORD_HOLDING_TIME
    #endif
    #ifndef RIGHT_RINGY_MIDDY_STREAK_DECAY
    #define RIGHT_RINGY_MIDDY_STREAK_DECAY RIGHT_RINGY_CHORD_STREAK_DECAY
    #endif
    #ifndef RIGHT_RINGY_MIDDY_REPEAT_DECAY
    #define RIGHT_RINGY_MIDDY_REPEAT_DECAY RIGHT_RINGY_CHORD_REPEAT_DECAY
    #endif
    right_ringy_middy: homey_right_ringy_middy {
      compatible = "zmk,behavior-hold-tap";
      flavor = RIGHT_RINGY_HOLDING_TYPE;
      hold-trigger-key-positions = <LEFT_HAND_KEYS THUMB_KEYS>;
      hold-trigger-on-release; // wait for other home row mods
      tapping-term-ms = <RIGHT_RINGY_HOLDING_TIME>;
      quick-tap-ms = <RIGHT_RINGY_REPEAT_DECAY>;
      require-prior-idle-ms = <RIGHT_RINGY_STREAK_DECAY>;
      #binding-cells = <2>;
      bindings = <&kp>, <&kp>;
    };
    right_ringy_middy_bilateral: homey_right_ringy_middy_bilateral {
      compatible = "zmk,behavior-hold-tap";
      flavor = RIGHT_RINGY_HOLDING_TYPE;
      hold-trigger-key-positions = <LEFT_HAND_KEYS THUMB_KEYS>;
      hold-trigger-on-release; // wait for other home row mods
      tapping-term-ms = <RIGHT_RINGY_HOLDING_TIME>;
      quick-tap-ms = <RIGHT_RINGY_REPEAT_DECAY>;
      require-prior-idle-ms = <RIGHT_RINGY_STREAK_DECAY>;
      #binding-cells = <2>;
      bindings = <&kp>, <&right_ringy_tap>;
    };
    #define RightRingyMiddy right_ringy_middy_bilateral RIGHT_MIDDY_MOD RIGHT_MIDDY_KEY
    #ifndef RIGHT_INDEX_MIDDY_HOLDING_TYPE
    #define RIGHT_INDEX_MIDDY_HOLDING_TYPE RIGHT_INDEX_CHORD_HOLDING_TYPE
    #endif
    #ifndef RIGHT_INDEX_MIDDY_HOLDING_TIME
    #define RIGHT_INDEX_MIDDY_HOLDING_TIME RIGHT_INDEX_CHORD_HOLDING_TIME
    #endif
    #ifndef RIGHT_INDEX_MIDDY_STREAK_DECAY
    #define RIGHT_INDEX_MIDDY_STREAK_DECAY RIGHT_INDEX_CHORD_STREAK_DECAY
    #endif
    #ifndef RIGHT_INDEX_MIDDY_REPEAT_DECAY
    #define RIGHT_INDEX_MIDDY_REPEAT_DECAY RIGHT_INDEX_CHORD_REPEAT_DECAY
    #endif
    right_index_middy: homey_right_index_middy {
      compatible = "zmk,behavior-hold-tap";
      flavor = RIGHT_INDEX_HOLDING_TYPE;
      hold-trigger-key-positions = <LEFT_HAND_KEYS THUMB_KEYS>;
      hold-trigger-on-release; // wait for other home row mods
      tapping-term-ms = <RIGHT_INDEX_HOLDING_TIME>;
      quick-tap-ms = <RIGHT_INDEX_REPEAT_DECAY>;
      require-prior-idle-ms = <RIGHT_INDEX_STREAK_DECAY>;
      #binding-cells = <2>;
      bindings = <&kp>, <&kp>;
    };
    right_index_middy_bilateral: homey_right_index_middy_bilateral {
      compatible = "zmk,behavior-hold-tap";
      flavor = RIGHT_INDEX_HOLDING_TYPE;
      hold-trigger-key-positions = <LEFT_HAND_KEYS THUMB_KEYS>;
      hold-trigger-on-release; // wait for other home row mods
      tapping-term-ms = <RIGHT_INDEX_HOLDING_TIME>;
      quick-tap-ms = <RIGHT_INDEX_REPEAT_DECAY>;
      require-prior-idle-ms = <RIGHT_INDEX_STREAK_DECAY>;
      #binding-cells = <2>;
      bindings = <&kp>, <&right_index_tap>;
    };
    #define RightIndexMiddy right_index_middy_bilateral RIGHT_MIDDY_MOD RIGHT_MIDDY_KEY
    #ifndef LEFT_PINKY_INDEX_HOLDING_TYPE
    #define LEFT_PINKY_INDEX_HOLDING_TYPE LEFT_PINKY_CHORD_HOLDING_TYPE
    #endif
    #ifndef LEFT_PINKY_INDEX_HOLDING_TIME
    #define LEFT_PINKY_INDEX_HOLDING_TIME LEFT_PINKY_CHORD_HOLDING_TIME
    #endif
    #ifndef LEFT_PINKY_INDEX_STREAK_DECAY
    #define LEFT_PINKY_INDEX_STREAK_DECAY LEFT_PINKY_CHORD_STREAK_DECAY
    #endif
    #ifndef LEFT_PINKY_INDEX_REPEAT_DECAY
    #define LEFT_PINKY_INDEX_REPEAT_DECAY LEFT_PINKY_CHORD_REPEAT_DECAY
    #endif
    left_pinky_index: homey_left_pinky_index {
      compatible = "zmk,behavior-hold-tap";
      flavor = LEFT_PINKY_HOLDING_TYPE;
      hold-trigger-key-positions = <RIGHT_HAND_KEYS THUMB_KEYS>;
      hold-trigger-on-release; // wait for other home row mods
      tapping-term-ms = <LEFT_PINKY_HOLDING_TIME>;
      quick-tap-ms = <LEFT_PINKY_REPEAT_DECAY>;
      require-prior-idle-ms = <LEFT_PINKY_STREAK_DECAY>;
      #binding-cells = <2>;
      bindings = <&kp>, <&kp>;
    };
    left_pinky_index_bilateral: homey_left_pinky_index_bilateral {
      compatible = "zmk,behavior-hold-tap";
      flavor = LEFT_PINKY_HOLDING_TYPE;
      hold-trigger-key-positions = <RIGHT_HAND_KEYS THUMB_KEYS>;
      hold-trigger-on-release; // wait for other home row mods
      tapping-term-ms = <LEFT_PINKY_HOLDING_TIME>;
      quick-tap-ms = <LEFT_PINKY_REPEAT_DECAY>;
      require-prior-idle-ms = <LEFT_PINKY_STREAK_DECAY>;
      #binding-cells = <2>;
      bindings = <&kp>, <&left_pinky_tap>;
    };
    #define LeftPinkyIndex left_pinky_index_bilateral LEFT_INDEX_MOD LEFT_INDEX_KEY
    #ifndef LEFT_RINGY_INDEX_HOLDING_TYPE
    #define LEFT_RINGY_INDEX_HOLDING_TYPE LEFT_RINGY_CHORD_HOLDING_TYPE
    #endif
    #ifndef LEFT_RINGY_INDEX_HOLDING_TIME
    #define LEFT_RINGY_INDEX_HOLDING_TIME LEFT_RINGY_CHORD_HOLDING_TIME
    #endif
    #ifndef LEFT_RINGY_INDEX_STREAK_DECAY
    #define LEFT_RINGY_INDEX_STREAK_DECAY LEFT_RINGY_CHORD_STREAK_DECAY
    #endif
    #ifndef LEFT_RINGY_INDEX_REPEAT_DECAY
    #define LEFT_RINGY_INDEX_REPEAT_DECAY LEFT_RINGY_CHORD_REPEAT_DECAY
    #endif
    left_ringy_index: homey_left_ringy_index {
      compatible = "zmk,behavior-hold-tap";
      flavor = LEFT_RINGY_HOLDING_TYPE;
      hold-trigger-key-positions = <RIGHT_HAND_KEYS THUMB_KEYS>;
      hold-trigger-on-release; // wait for other home row mods
      tapping-term-ms = <LEFT_RINGY_HOLDING_TIME>;
      quick-tap-ms = <LEFT_RINGY_REPEAT_DECAY>;
      require-prior-idle-ms = <LEFT_RINGY_STREAK_DECAY>;
      #binding-cells = <2>;
      bindings = <&kp>, <&kp>;
    };
    left_ringy_index_bilateral: homey_left_ringy_index_bilateral {
      compatible = "zmk,behavior-hold-tap";
      flavor = LEFT_RINGY_HOLDING_TYPE;
      hold-trigger-key-positions = <RIGHT_HAND_KEYS THUMB_KEYS>;
      hold-trigger-on-release; // wait for other home row mods
      tapping-term-ms = <LEFT_RINGY_HOLDING_TIME>;
      quick-tap-ms = <LEFT_RINGY_REPEAT_DECAY>;
      require-prior-idle-ms = <LEFT_RINGY_STREAK_DECAY>;
      #binding-cells = <2>;
      bindings = <&kp>, <&left_ringy_tap>;
    };
    #define LeftRingyIndex left_ringy_index_bilateral LEFT_INDEX_MOD LEFT_INDEX_KEY
    #ifndef LEFT_MIDDY_INDEX_HOLDING_TYPE
    #define LEFT_MIDDY_INDEX_HOLDING_TYPE LEFT_MIDDY_CHORD_HOLDING_TYPE
    #endif
    #ifndef LEFT_MIDDY_INDEX_HOLDING_TIME
    #define LEFT_MIDDY_INDEX_HOLDING_TIME LEFT_MIDDY_CHORD_HOLDING_TIME
    #endif
    #ifndef LEFT_MIDDY_INDEX_STREAK_DECAY
    #define LEFT_MIDDY_INDEX_STREAK_DECAY LEFT_MIDDY_CHORD_STREAK_DECAY
    #endif
    #ifndef LEFT_MIDDY_INDEX_REPEAT_DECAY
    #define LEFT_MIDDY_INDEX_REPEAT_DECAY LEFT_MIDDY_CHORD_REPEAT_DECAY
    #endif
    left_middy_index: homey_left_middy_index {
      compatible = "zmk,behavior-hold-tap";
      flavor = LEFT_MIDDY_HOLDING_TYPE;
      hold-trigger-key-positions = <RIGHT_HAND_KEYS THUMB_KEYS>;
      hold-trigger-on-release; // wait for other home row mods
      tapping-term-ms = <LEFT_MIDDY_HOLDING_TIME>;
      quick-tap-ms = <LEFT_MIDDY_REPEAT_DECAY>;
      require-prior-idle-ms = <LEFT_MIDDY_STREAK_DECAY>;
      #binding-cells = <2>;
      bindings = <&kp>, <&kp>;
    };
    left_middy_index_bilateral: homey_left_middy_index_bilateral {
      compatible = "zmk,behavior-hold-tap";
      flavor = LEFT_MIDDY_HOLDING_TYPE;
      hold-trigger-key-positions = <RIGHT_HAND_KEYS THUMB_KEYS>;
      hold-trigger-on-release; // wait for other home row mods
      tapping-term-ms = <LEFT_MIDDY_HOLDING_TIME>;
      quick-tap-ms = <LEFT_MIDDY_REPEAT_DECAY>;
      require-prior-idle-ms = <LEFT_MIDDY_STREAK_DECAY>;
      #binding-cells = <2>;
      bindings = <&kp>, <&left_middy_tap>;
    };
    #define LeftMiddyIndex left_middy_index_bilateral LEFT_INDEX_MOD LEFT_INDEX_KEY
    #ifndef RIGHT_PINKY_INDEX_HOLDING_TYPE
    #define RIGHT_PINKY_INDEX_HOLDING_TYPE RIGHT_PINKY_CHORD_HOLDING_TYPE
    #endif
    #ifndef RIGHT_PINKY_INDEX_HOLDING_TIME
    #define RIGHT_PINKY_INDEX_HOLDING_TIME RIGHT_PINKY_CHORD_HOLDING_TIME
    #endif
    #ifndef RIGHT_PINKY_INDEX_STREAK_DECAY
    #define RIGHT_PINKY_INDEX_STREAK_DECAY RIGHT_PINKY_CHORD_STREAK_DECAY
    #endif
    #ifndef RIGHT_PINKY_INDEX_REPEAT_DECAY
    #define RIGHT_PINKY_INDEX_REPEAT_DECAY RIGHT_PINKY_CHORD_REPEAT_DECAY
    #endif
    right_pinky_index: homey_right_pinky_index {
      compatible = "zmk,behavior-hold-tap";
      flavor = RIGHT_PINKY_HOLDING_TYPE;
      hold-trigger-key-positions = <LEFT_HAND_KEYS THUMB_KEYS>;
      hold-trigger-on-release; // wait for other home row mods
      tapping-term-ms = <RIGHT_PINKY_HOLDING_TIME>;
      quick-tap-ms = <RIGHT_PINKY_REPEAT_DECAY>;
      require-prior-idle-ms = <RIGHT_PINKY_STREAK_DECAY>;
      #binding-cells = <2>;
      bindings = <&kp>, <&kp>;
    };
    right_pinky_index_bilateral: homey_right_pinky_index_bilateral {
      compatible = "zmk,behavior-hold-tap";
      flavor = RIGHT_PINKY_HOLDING_TYPE;
      hold-trigger-key-positions = <LEFT_HAND_KEYS THUMB_KEYS>;
      hold-trigger-on-release; // wait for other home row mods
      tapping-term-ms = <RIGHT_PINKY_HOLDING_TIME>;
      quick-tap-ms = <RIGHT_PINKY_REPEAT_DECAY>;
      require-prior-idle-ms = <RIGHT_PINKY_STREAK_DECAY>;
      #binding-cells = <2>;
      bindings = <&kp>, <&right_pinky_tap>;
    };
    #define RightPinkyIndex right_pinky_index_bilateral RIGHT_INDEX_MOD RIGHT_INDEX_KEY
    #ifndef RIGHT_RINGY_INDEX_HOLDING_TYPE
    #define RIGHT_RINGY_INDEX_HOLDING_TYPE RIGHT_RINGY_CHORD_HOLDING_TYPE
    #endif
    #ifndef RIGHT_RINGY_INDEX_HOLDING_TIME
    #define RIGHT_RINGY_INDEX_HOLDING_TIME RIGHT_RINGY_CHORD_HOLDING_TIME
    #endif
    #ifndef RIGHT_RINGY_INDEX_STREAK_DECAY
    #define RIGHT_RINGY_INDEX_STREAK_DECAY RIGHT_RINGY_CHORD_STREAK_DECAY
    #endif
    #ifndef RIGHT_RINGY_INDEX_REPEAT_DECAY
    #define RIGHT_RINGY_INDEX_REPEAT_DECAY RIGHT_RINGY_CHORD_REPEAT_DECAY
    #endif
    right_ringy_index: homey_right_ringy_index {
      compatible = "zmk,behavior-hold-tap";
      flavor = RIGHT_RINGY_HOLDING_TYPE;
      hold-trigger-key-positions = <LEFT_HAND_KEYS THUMB_KEYS>;
      hold-trigger-on-release; // wait for other home row mods
      tapping-term-ms = <RIGHT_RINGY_HOLDING_TIME>;
      quick-tap-ms = <RIGHT_RINGY_REPEAT_DECAY>;
      require-prior-idle-ms = <RIGHT_RINGY_STREAK_DECAY>;
      #binding-cells = <2>;
      bindings = <&kp>, <&kp>;
    };
    right_ringy_index_bilateral: homey_right_ringy_index_bilateral {
      compatible = "zmk,behavior-hold-tap";
      flavor = RIGHT_RINGY_HOLDING_TYPE;
      hold-trigger-key-positions = <LEFT_HAND_KEYS THUMB_KEYS>;
      hold-trigger-on-release; // wait for other home row mods
      tapping-term-ms = <RIGHT_RINGY_HOLDING_TIME>;
      quick-tap-ms = <RIGHT_RINGY_REPEAT_DECAY>;
      require-prior-idle-ms = <RIGHT_RINGY_STREAK_DECAY>;
      #binding-cells = <2>;
      bindings = <&kp>, <&right_ringy_tap>;
    };
    #define RightRingyIndex right_ringy_index_bilateral RIGHT_INDEX_MOD RIGHT_INDEX_KEY
    #ifndef RIGHT_MIDDY_INDEX_HOLDING_TYPE
    #define RIGHT_MIDDY_INDEX_HOLDING_TYPE RIGHT_MIDDY_CHORD_HOLDING_TYPE
    #endif
    #ifndef RIGHT_MIDDY_INDEX_HOLDING_TIME
    #define RIGHT_MIDDY_INDEX_HOLDING_TIME RIGHT_MIDDY_CHORD_HOLDING_TIME
    #endif
    #ifndef RIGHT_MIDDY_INDEX_STREAK_DECAY
    #define RIGHT_MIDDY_INDEX_STREAK_DECAY RIGHT_MIDDY_CHORD_STREAK_DECAY
    #endif
    #ifndef RIGHT_MIDDY_INDEX_REPEAT_DECAY
    #define RIGHT_MIDDY_INDEX_REPEAT_DECAY RIGHT_MIDDY_CHORD_REPEAT_DECAY
    #endif
    right_middy_index: homey_right_middy_index {
      compatible = "zmk,behavior-hold-tap";
      flavor = RIGHT_MIDDY_HOLDING_TYPE;
      hold-trigger-key-positions = <LEFT_HAND_KEYS THUMB_KEYS>;
      hold-trigger-on-release; // wait for other home row mods
      tapping-term-ms = <RIGHT_MIDDY_HOLDING_TIME>;
      quick-tap-ms = <RIGHT_MIDDY_REPEAT_DECAY>;
      require-prior-idle-ms = <RIGHT_MIDDY_STREAK_DECAY>;
      #binding-cells = <2>;
      bindings = <&kp>, <&kp>;
    };
    right_middy_index_bilateral: homey_right_middy_index_bilateral {
      compatible = "zmk,behavior-hold-tap";
      flavor = RIGHT_MIDDY_HOLDING_TYPE;
      hold-trigger-key-positions = <LEFT_HAND_KEYS THUMB_KEYS>;
      hold-trigger-on-release; // wait for other home row mods
      tapping-term-ms = <RIGHT_MIDDY_HOLDING_TIME>;
      quick-tap-ms = <RIGHT_MIDDY_REPEAT_DECAY>;
      require-prior-idle-ms = <RIGHT_MIDDY_STREAK_DECAY>;
      #binding-cells = <2>;
      bindings = <&kp>, <&right_middy_tap>;
    };
    #define RightMiddyIndex right_middy_index_bilateral RIGHT_INDEX_MOD RIGHT_INDEX_KEY
  };
};
